[part 2 of 2]
AUTOSAR XML (schema 4-2-1)
package /GeneralMotorsPkg/GeneralMotorsArchitecturePkg/GeneralMotorsVehicleAbstractionPkg
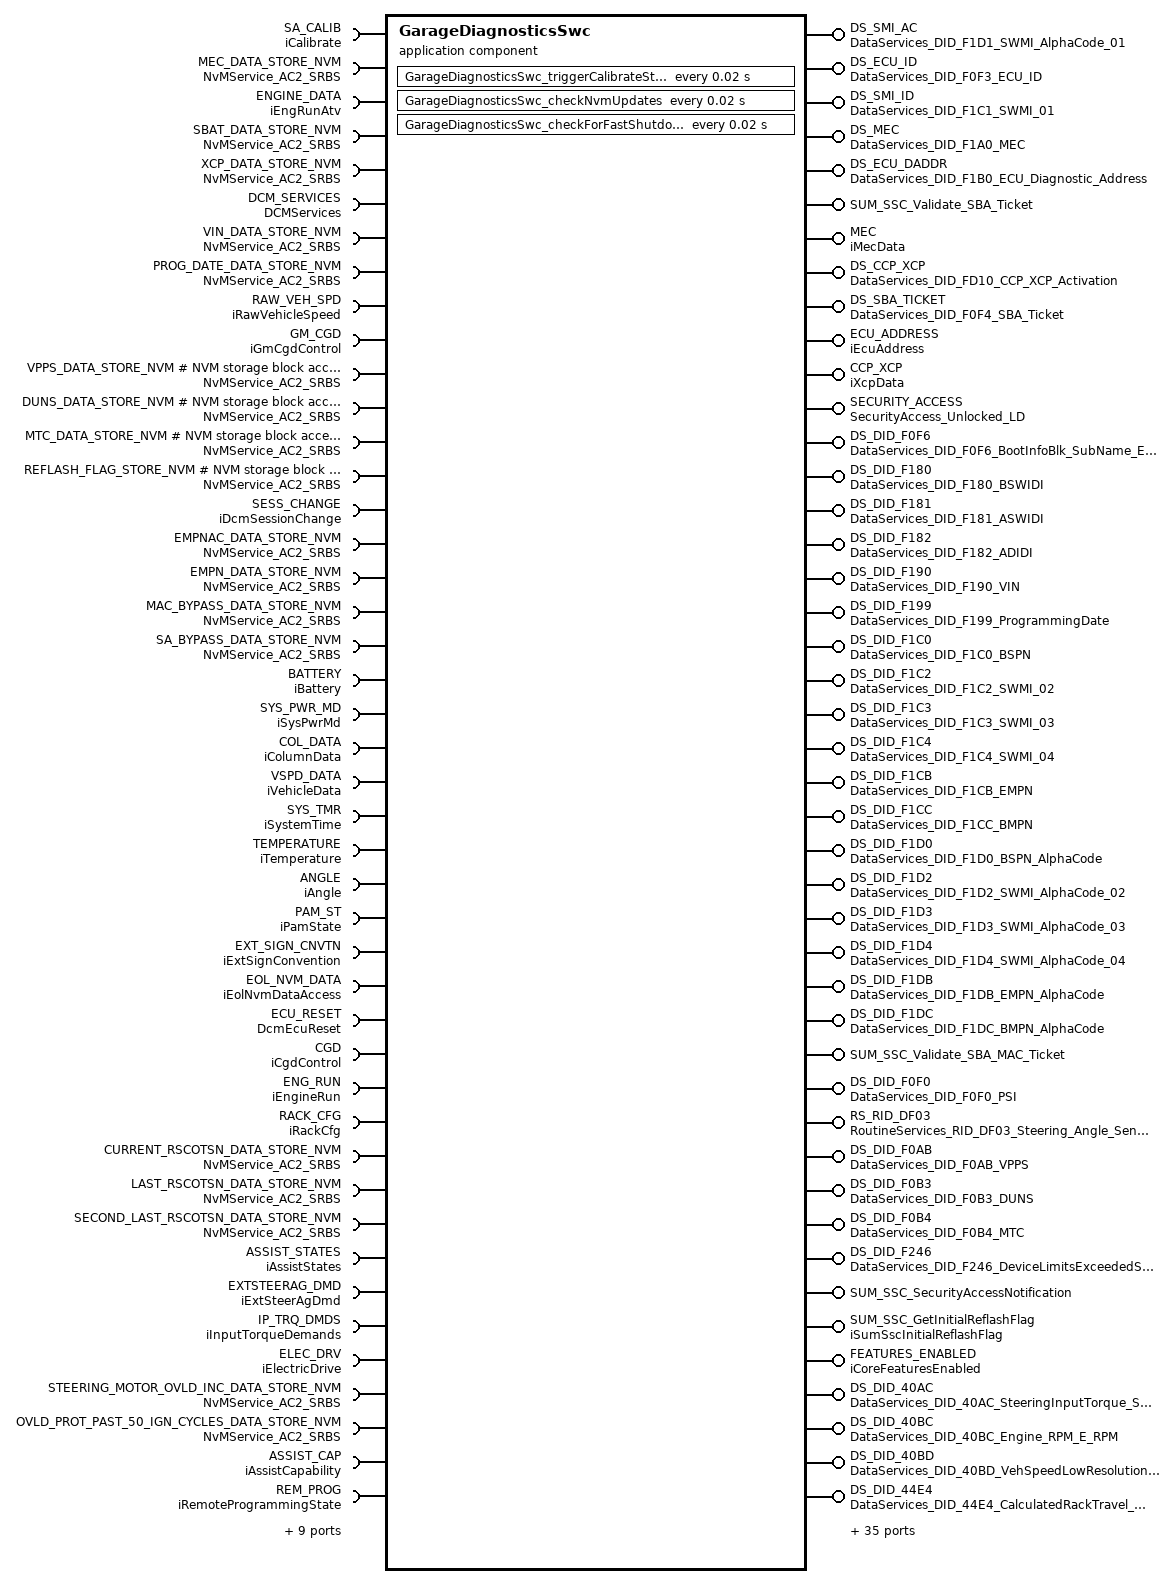
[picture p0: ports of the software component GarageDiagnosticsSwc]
  application sw component type GarageDiagnosticsSwc  # Garage Diagnostic allows the garage engineer to interface with the ECU software
    require port SA_CALIB: required-interface=iCalibrate  # Interface to call straight ahead calibration
    7 x provide port:
      DS_SMI_AC: server-com-spec{operation=ReadData, queue-length=1}, provided-interface=DataServices_DID_F1D1_SWMI_AlphaCode_01  # Full name: DataServices_Software_Module_Identifier_Alpha_Code_01_SWMI_AlphaCode_01
      DS_ECU_ID: server-com-spec{operation=ReadData, queue-length=1}, provided-interface=DataServices_DID_F0F3_ECU_ID  # Full name: DataServices_ECU_ID_EcuID
      DS_SMI_ID: server-com-spec{operation=ReadData, queue-length=1}, provided-interface=DataServices_DID_F1C1_SWMI_01  # Full name: DataServices_Software_Module_Identifier_01_SWMI_01
      DS_MEC: provided-com-specs=[{operation=ReadData, queue-length=1}, {operation=WriteData, queue-length=1}], provided-interface=DataServices_DID_F1A0_MEC  # Full name: DataServices_Manufacturers_Enable_Counter_MEC
      DS_ECU_DADDR: server-com-spec{operation=ReadData, queue-length=1}, provided-interface=DataServices_DID_F1B0_ECU_Diagnostic_Address  # Full name: DataServices_ECU_Diagnostic_Address_ECU_Address
      SUM_SSC_Validate_SBA_Ticket: server-com-spec{operation=Validate_SBA_Ticket, queue-length=1}, provided-interface=SUM_SSC_Validate_SBA_Ticket  # Interface used by SUM_SSC to validate all Security Bypass Authentication (SBA) Ticket
      MEC: nonqueued-sender-com-spec{data-element=MEC, init-value=constant-reference=iMecData_MEC_Init}, provided-interface=iMecData  # This port is used to allow the SUM_SSC access to the MEC value that is stored in the RTE. This is externally connected to SUM_DIAG_GetMEC
    require port MEC_DATA_STORE_NVM: required-interface=NvMService_AC2_SRBS  # Interface to access NVM store
    provide port DS_CCP_XCP: provided-com-specs=[{operation=ReadData, queue-length=1}, {operation=WriteData, queue-length=1}], provided-interface=DataServices_DID_FD10_CCP_XCP_Activation  # Full name: DataServices_CCP_XCP_Activation_CCP_XCP_Activation
    provide port DS_SBA_TICKET: provided-com-specs=[{operation=ReadData, queue-length=1}, {operation=WriteData, queue-length=1}], provided-interface=DataServices_DID_F0F4_SBA_Ticket  # Full name: DataServices_Signature_Bypass_Authorization_Ticket_SBATkt
    provide port ECU_ADDRESS: nonqueued-sender-com-spec{data-element=ECUAddress, init-value=constant-reference=iEcuAddress_ECUAddress_Init}, provided-interface=iEcuAddress  # This port is used to allow the SUM_SSC component to access the ECU Address. This is externally connected to SUM_SSC_GetECUAddress
    require port ENGINE_DATA: required-interface=iEngRunAtv  # Access to the engine data sent via CAN
      required-com-specs:
        data-element=EngineSpeed, init-value=constant-reference=iEngRunAtv_EngineSpeed_Init
        data-element=PowertrainCrankActive, init-value=constant-reference=iEngRunAtv_PowertrainCrankActive_Init
        data-element=Engine12VStarterMotorCmdOn, init-value=constant-reference=iEngRunAtv_Engine12VStarterMotorCmdOn_Init
    require port SBAT_DATA_STORE_NVM: required-interface=NvMService_AC2_SRBS  # Interface to access NVM store
    require port XCP_DATA_STORE_NVM: required-interface=NvMService_AC2_SRBS  # Interface to access NVM store
    provide port CCP_XCP: nonqueued-sender-com-spec{data-element=XcpStatus, init-value=constant-reference=iXcpData_XcpStatus_Init}, provided-interface=iXcpData  # Output the XCP status
    provide port SECURITY_ACCESS: provided-com-specs=[{operation=GetSeed, queue-length=1}, {operation=CompareKey, queue-length=1}], provided-interface=SecurityAccess_Unlocked_LD  # Security Access interfaces used by SUM_SSC
    require port DCM_SERVICES: required-interface=DCMServices  # Requests from the DCM component for CGD to do something
    18 x provide port:
      DS_DID_F0F6: server-com-spec{operation=ReadData, queue-length=1}, provided-interface=DataServices_DID_F0F6_BootInfoBlk_SubName_EcuName  # Boot Info Block Subject name and ECU name Subject name is an ECU family name. It is a 16 byte hexadecimal value that identifies the group of ECUs for which the Signer Info is applicable. It is used during the programming process to determine if the Signer Info is compatible with the target. Example: Powertrain, Infotainment, Telematics etc. ECU name is an 8 byte ASCII representation of the ECU name.
      DS_DID_F180: server-com-spec{operation=ReadData, queue-length=1}, provided-interface=DataServices_DID_F180_BSWIDI  # Boot Software Identification Data Identifier The BSWIDI is used to reference the vehicle-manufacturer-specific ECU boot software identification record. This DID is supported in all ECUs. The first data byte of the record data shall be the number of modules that are programmed in the ECU. If an ECU supports more than one BSWIDI at one time then this DID shall report the Fna, Part Number and DLS/PLS for each additional module. The numberOfModules shall reflect the total number of modules supported. If any modules are missing and the ECU can still report this DID the number of modules shall represent the number of modules that are currently programmed in the ECU. If no modules are programmed and the ECU can still report this DID the number of modules shall be zero. Note:The total number of bytes will vary depending on the number of modules programmed in the ECU.
      DS_DID_F181: server-com-spec{operation=ReadData, queue-length=1}, provided-interface=DataServices_DID_F181_ASWIDI  # Application Software Identification Data Identifier The ASWIDI is used to reference the vehicle-manufacturer-specific ECU application software identification record. This DID is supported in all ECUs as defined below. The first data byte of the data record shall be the total number of application software modules that are supported by the ECU. The application software module identification shall contain the Module Id, GM Part Number and GM Part Number Alpha Code as shown below. If an ECU supports more than one application software module then this DID shall report the Module Id , Part Number and Alpha Code for each additional application software module. If an application software module(s) is missing then the value of the application software module identification for the missing application software module(s) shall be zeroes. Note:The total number of bytes will vary depending on the number of modules programmed in the ECU.
      DS_DID_F182: server-com-spec{operation=ReadData, queue-length=1}, provided-interface=DataServices_DID_F182_ADIDI  # Application Data Identification Data Identifier The ADIDI is used to reference the vehicle-manufacturer-specific ECU calibration identification record. This DID is supported in all ECUs as defined below. The first data byte of the data record shall be the total number of calibration modules that are supported by the ECU. The calibration module identification shall contain the Module Id, GM Part Number and GM Part Number Alpha Code as shown below. If an ECU supports more than one calibration module then this DID shall report the Module Id, Part Number and Alpha Code for each additional calibration module. If a calibration module(s) is missing then the value of the calibration module identification for the missing calibration module(s) shall be zeroes. Note:The total number of bytes will vary depending on the number of modules programmed in the ECU.
      DS_DID_F190: provided-com-specs=[{operation=ReadData, queue-length=1}, {operation=WriteData, queue-length=1}], provided-interface=DataServices_DID_F190_VIN  # Vehicle Identification Number This DID contains the Vehicle Identification Number. The data content shall be specified by the vehicle manufacturer. If the VIN has not yet been programmed into the ECU permanent memory, those locations shall be either "$00" or "$FF". All 17 digits must be programmed in order for the ECU to use this DID.
      DS_DID_F199: provided-com-specs=[{operation=ReadData, queue-length=1}, {operation=WriteData, queue-length=1}], provided-interface=DataServices_DID_F199_ProgrammingDate  # Programming Date This DID contains the ProgrammingDate of the last programming event (SPS) at the dealer site. This BCD value is programmed into the ECU's memory during the last programming session (SPS).
      DS_DID_F1C0: server-com-spec{operation=ReadData, queue-length=1}, provided-interface=DataServices_DID_F1C0_BSPN  # BootSoftwarePartNumber (BSPN) This DID contains Boot Software Part Number information which is a 4-byte, unsigned numeric representation of the 8-digit GM part number assigned to the boot software of the ECU. If a Boot Software Alpha Code is used, then the Alpha Code associated with this part number shall be stored in DID $F1D0.
      DS_DID_F1C2: server-com-spec{operation=ReadData, queue-length=1}, provided-interface=DataServices_DID_F1C2_SWMI_02  # F1C2: SoftwareModule_02_Identifier This DID contains the Software Module Identifier (SWMI) 01 information used to uniquely identify a given software or calibration module. Each SWMI has a corresponding DID associated with it. ECUs are only required to support the DIDs which correspond to SWMIs valid for that ECU. The SWMI shall be included for each software module that can be separately programmed into the ECU permanent memory via the SPS. Individual software modules can contain operational software or calibration data. The SWMI information shall be stored using a four byte USN representation of the eight digit GM part number assigned to the software or calibration module. Each SWMI has a corresponding dataIdentifier associated with it. ECUs are only required to support the DIDs which correspond to SWMIs valid for that ECU.
      DS_DID_F1C3: server-com-spec{operation=ReadData, queue-length=1}, provided-interface=DataServices_DID_F1C3_SWMI_03  # F1C3: SoftwareModule_03_Identifier This DID contains the Software Module Identifier (SWMI) 01 information used to uniquely identify a given software or calibration module. Each SWMI has a corresponding DID associated with it. ECUs are only required to support the DIDs which correspond to SWMIs valid for that ECU. The SWMI shall be included for each software module that can be separately programmed into the ECU permanent memory via the SPS. Individual software modules can contain operational software or calibration data. The SWMI information shall be stored using a four byte USN representation of the eight digit GM part number assigned to the software or calibration module. Each SWMI has a corresponding dataIdentifier associated with it. ECUs are only required to support the DIDs which correspond to SWMIs valid for that ECU.
      DS_DID_F1C4: server-com-spec{operation=ReadData, queue-length=1}, provided-interface=DataServices_DID_F1C4_SWMI_04  # F1C4: SoftwareModule_04_Identifier This DID contains the Software Module Identifier (SWMI) 01 information used to uniquely identify a given software or calibration module. Each SWMI has a corresponding DID associated with it. ECUs are only required to support the DIDs which correspond to SWMIs valid for that ECU. The SWMI shall be included for each software module that can be separately programmed into the ECU permanent memory via the SPS. Individual software modules can contain operational software or calibration data. The SWMI information shall be stored using a four byte USN representation of the eight digit GM part number assigned to the software or calibration module. Each SWMI has a corresponding dataIdentifier associated with it. ECUs are only required to support the DIDs which correspond to SWMIs valid for that ECU.
      DS_DID_F1CB: server-com-spec{operation=ReadData, queue-length=1}, provided-interface=DataServices_DID_F1CB_EMPN  # End Model Part Number This DID is used to identify the part number that represents the combination of hardware/software/calibrations present in the ECU as it is received in the vehicle assembly plant. This part number is also used in service to uniquely identify the combination of hardware/software/calibrations programmed into the ECU at the time the part is ordered. Converting the four byte USN value to decimal provides the 8-digit part number assigned by the division. If an Alpha Code is used, then the Alpha Code associated with this part number shall be stored in dataIdentifier 0xF1DB.
      DS_DID_F1CC: server-com-spec{operation=ReadData, queue-length=1}, provided-interface=DataServices_DID_F1CC_BMPN  # Base Model Part Number This DID contains Base Model Part Number information which is used during SPS programming to identify a unique combination of ECU hardware and all non-reprogrammable software (e.g., Boot software). The BMPN must be stored in the ECU in a non-erasable memory area (e.g., boot sector of flash, or EEPROM). It shall not be possible to change the BMPN as part of a programming session or through diagnostic services when a programming session is not active. The BMPN of a service replacement ECU shall be identical to that of a Production ECU if both ECUs have the same hardware and non-reprogrammable software. If an Alpha Code is used, then the Alpha Code associated with this part number shall be stored in dataIdentifier $F1DC.
      DS_DID_F1D0: server-com-spec{operation=ReadData, queue-length=1}, provided-interface=DataServices_DID_F1D0_BSPN_AlphaCode  # Boot Software Part Number Alpha Code This DID contains a 2 character ASCII representation of the Alpha Code associated with the Boot Software Part Number (stored in DID 0xF1C0). The Alpha Code consists of a Design Level Suffix (DLS) and a Process Level Suffix (PLS). Byte 1 (DLS) This byte is contains an ASCII value that represents the major software release. This value shall initially be set to A and incremented as appropriate. Byte 2 (PLS) This byte is contains an ASCII value that represents the minor software revision. This value shall initially be set to A and incremented as appropriate.
      DS_DID_F1D2: server-com-spec{operation=ReadData, queue-length=1}, provided-interface=DataServices_DID_F1D2_SWMI_AlphaCode_02  # F1D2: SoftwareModule_02_AlphaCode This DID contains a 2 character ASCII representation of the Alpha Code for the corresponding Software Module Identifier 01-10, DID 0xF1C1 - 0xF1CA. The Alpha Code consists of a Design Level Suffix (DLS) and a Process Level Suffix (PLS). The SWMIs occupy the dataIdentifier range $F1C1 thru $F1CA. Reference the SWMI DID description for the numerical relationship between the DIDs used for the SWMI and the corresponding SWMIAC.
      DS_DID_F1D3: server-com-spec{operation=ReadData, queue-length=1}, provided-interface=DataServices_DID_F1D3_SWMI_AlphaCode_03  # F1D3: SoftwareModule_03_AlphaCode This DID contains a 2 character ASCII representation of the Alpha Code for the corresponding Software Module Identifier 01-10, DID 0xF1C1 - 0xF1CA. The Alpha Code consists of a Design Level Suffix (DLS) and a Process Level Suffix (PLS). The SWMIs occupy the dataIdentifier range $F1C1 thru $F1CA. Reference the SWMI DID description for the numerical relationship between the DIDs used for the SWMI and the corresponding SWMIAC.
      DS_DID_F1D4: server-com-spec{operation=ReadData, queue-length=1}, provided-interface=DataServices_DID_F1D4_SWMI_AlphaCode_04  # F1D4: SoftwareModule_04_AlphaCode This DID contains a 2 character ASCII representation of the Alpha Code for the corresponding Software Module Identifier 01-10, DID 0xF1C1 - 0xF1CA. The Alpha Code consists of a Design Level Suffix (DLS) and a Process Level Suffix (PLS). The SWMIs occupy the dataIdentifier range $F1C1 thru $F1CA. Reference the SWMI DID description for the numerical relationship between the DIDs used for the SWMI and the corresponding SWMIAC.
      DS_DID_F1DB: server-com-spec{operation=ReadData, queue-length=1}, provided-interface=DataServices_DID_F1DB_EMPN_AlphaCode  # End Model Part Number Alpha Code This DID contains the 2 character ASCII representation of the Alpha Code associated with the End Model Part Number (stored in DID 0XF1CB). The Alpha Code consists of a Design Level Suffix (DLS) and a Process Level Suffix (PLS). Byte 1 (DLS): This byte is contains an ASCII value that represents the hardware release. This value shall initially be set to A and incremented for a hardware revision. Byte 2 (PLS): This byte is contains an ASCII value that represents the software release. This value shall initially be set to A and incremented for a software revision.
      DS_DID_F1DC: server-com-spec{operation=ReadData, queue-length=1}, provided-interface=DataServices_DID_F1DC_BMPN_AlphaCode  # Base Model Part Number Alpha Code This DID contains the 2 character ASCII representation of the Alpha Code associated with the Base Model Part Number (stored in DID 0Xf1CC). The Alpha Code consists of a Design Level Suffix (DLS) and a Process Level Suffix (PLS). Byte 1 (DLS): This byte is contains an ASCII value that represents the hardware release. This value shall initially be set to A and incremented for a hardware revision. Byte 2 (PLS): This byte is contains an ASCII value that represents the software release. This value shall initially be set to A and incremented for a software revision.
    require port VIN_DATA_STORE_NVM: required-interface=NvMService_AC2_SRBS  # Interface to access NVM store
    require port PROG_DATE_DATA_STORE_NVM: required-interface=NvMService_AC2_SRBS  # Interface to access NVM store
    provide port SUM_SSC_Validate_SBA_MAC_Ticket: server-com-spec{operation=Validate_SBA_MAC_Ticket, queue-length=1}, provided-interface=SUM_SSC_Validate_SBA_MAC_Ticket  # Interface used by SUM_SSC to validate an individual MAC message Security Bypass Authentication (SBA) Ticket
    provide port DS_DID_F0F0: server-com-spec{operation=ReadData, queue-length=1}, provided-interface=DataServices_DID_F0F0_PSI  # ProgrammedStateIndicator (PSI) The Programmed State Indicator (PSI) data identifier provides a reliable mechanism for a Tester to determine if a logical partition is programmed with a valid content (i.e. Application software or calibration data). Each logical partition has a dedicated PSI that can be read using this DID. This means that there exist a PSI for application software partition and a PSI per calibration partition. This DID contains the ProgrammedStateIndicator. The Programmed State Indicator is a reserved cell (the last two bytes) in a flash partition that indicates the validity of the content for that partition. Each partition has a dedicated PSI that can be read using this DID. The first byte of the PSI DID denotes the partition number for the PSI that is being requested. Partition Number further defines a 4bit MSB and 4 Bit LSB. The 4 bit MSB defines the Processor ID (0: main processor, 1: 2nd processor, 2 : 3rd processor, etc..) and the 4 bit LSB defines the partition number (1: Application, 2: 1st cal partition, 3: 2nd cal partition, etc ..). For example Partition Numbers (in hex) have the following meaning. 0x01 : Main processor Application SW Partition 0x02 : Main processor 1st Cal Partition 0x03 : Main processor 2nd Cal Partition .. 0x11 : 2nd processor Application SW Partition 0x12 : 2nd processor 1st Cal Partition 0x13 : 2rd processor 2nd Cal Partition The second byte of the PSI DID denotes the programmed state of the partition. $00 = Valid programming present $01 = programming has been revoked $02 = programming is invalid $03 - $FF = Reserved Subsequent group of two bytes denote next calibration partition and the programmed state of the partition respectively. This pattern sequentially repeats for next partition and programmed state until 255th partition and its programmed state.
    require port RAW_VEH_SPD: nonqueued-receiver-com-spec{data-element=iRawVehicleSpeed/VehicleSpeed, init-value=constant-reference=iRawVehicleSpeed_VehicleSpeed_Init}, required-interface=iRawVehicleSpeed  # Access to the raw vehicle speed
    require port GM_CGD: required-interface=iGmCgdControl  # Tells the rest of the software that reset or switch to factory assist has been requested
    5 x provide port:
      RS_RID_DF03: provided-com-specs=[{operation=Start, queue-length=1}, {operation=RequestResults, queue-length=1}], provided-interface=RoutineServices_RID_DF03_Steering_Angle_Sensor_Calibration  # RoutineServices_RID_DF03_Steering_Angle_Sensor_Calibration_Start
      DS_DID_F0AB: server-com-spec{operation=ReadData, queue-length=1}, provided-interface=DataServices_DID_F0AB_VPPS  # DID 0xF0AB VPPS : Read : Interface to Nvm with 14 bytes and default value shall be taken from CGD : 2 0 . 0 1 . 0 4 . 9 7 0 0 X : Should be possible to be updated via XCP
      DS_DID_F0B3: server-com-spec{operation=ReadData, queue-length=1}, provided-interface=DataServices_DID_F0B3_DUNS  # DID 0xF0B3 DUNS : Read : Interface to Nvm with 9 bytes and default value shall be taken from CGD : 914666552 : Should be possible to be updated via XCP
      DS_DID_F0B4: server-com-spec{operation=ReadData, queue-length=1}, provided-interface=DataServices_DID_F0B4_MTC  # DID 0xF0B4 MTC : Read : Interface to Nvm with 16 bytes and default value shall be taken from CGD : all bytes "X" : Should be possible to be updated via XCP
      DS_DID_F246: server-com-spec{operation=ReadData, queue-length=1}, provided-interface=DataServices_DID_F246_DeviceLimitsExceededStatus  # DID 0xF246 Device Limits Exceeded : Should be accessed through 2 global variables shared with part Straight Ahead : 1) Routine Identifier(2 bytes) 2) Device Limits Exceeded Code (2 bytes):
    4 x require port, all with required-interface=NvMService_AC2_SRBS:
      VPPS_DATA_STORE_NVM  # NVM storage block access port for Compressed Vehicle Partitioning and Product Structure (VPPS)
      DUNS_DATA_STORE_NVM  # NVM storage block access port for Data Universal Numbering System Identification (DUNS)
      MTC_DATA_STORE_NVM  # NVM storage block access port for ManufacturingTraceabilityCharacters (MTC)
      REFLASH_FLAG_STORE_NVM  # NVM storage block access port for InitialReflashFlag
    provide port SUM_SSC_SecurityAccessNotification: server-com-spec{operation=ClearInitialReflashFlag, queue-length=1}, provided-interface=SUM_SSC_SecurityAccessNotification  # Interface between CGD and SUM_SSC to allow the SSC to clear the InitialReflashFlag
    provide port SUM_SSC_GetInitialReflashFlag: nonqueued-sender-com-spec{data-element=InitialReflashFlag, init-value=constant-reference=iSumSscInitialReflashFlag_InitialReflashFlag_Init}, provided-interface=iSumSscInitialReflashFlag  # Allows the SUM_SSC to get the InitialReflashFlag
    5 x require port:
      SESS_CHANGE: required-interface=iDcmSessionChange  # Session Change, informs CGD that the diagnostic session has changed.
      EMPNAC_DATA_STORE_NVM: required-interface=NvMService_AC2_SRBS  # NVM storage block access port for End Model Part Number Alpha Code (EMPNAC)
      EMPN_DATA_STORE_NVM: required-interface=NvMService_AC2_SRBS  # NVM storage block access port for End Model Part Number (EMPN)
      MAC_BYPASS_DATA_STORE_NVM: required-interface=NvMService_AC2_SRBS  # NVM storage block access port for Message Authentication Code (MAC) Bypass
      SA_BYPASS_DATA_STORE_NVM: required-interface=NvMService_AC2_SRBS  # NVM storage block access port for Security Access (SA) Bypass
    29 x provide port:
      FEATURES_ENABLED: provided-interface=iCoreFeaturesEnabled  # Tells the component if the feature has been enabled or not.
        provided-com-specs:
          data-element=DisturbanceRejectionEnabled, init-value=constant-reference=iCoreFeaturesEnabled_DisturbanceRejectionEnabled_Init
          data-element=DriverSteeringRecommendationEnabled, init-value=constant-reference=iCoreFeaturesEnabled_DriverSteeringRecommendationEnabled_Init
          data-element=FrictionCompensationEnabled, init-value=constant-reference=iCoreFeaturesEnabled_FrictionCompensationEnabled_Init
          data-element=HapticVibrationGeneratorEnabled, init-value=constant-reference=iCoreFeaturesEnabled_HapticVibrationGeneratorEnabled_Init
          data-element=LaneKeepingAssistEnabled, init-value=constant-reference=iCoreFeaturesEnabled_LaneKeepingAssistEnabled_Init
          data-element=ParkAssistEnabled, init-value=constant-reference=iCoreFeaturesEnabled_ParkAssistEnabled_Init
          data-element=PullDriftCompensationEnabled, init-value=constant-reference=iCoreFeaturesEnabled_PullDriftCompensationEnabled_Init
          data-element=RackEndStopEnabled, init-value=constant-reference=iCoreFeaturesEnabled_RackEndStopEnabled_Init
          data-element=RapidControlPrototypingEnabled, init-value=constant-reference=iCoreFeaturesEnabled_RapidControlPrototypingEnabled_Init
          data-element=SteerFeelSelectionEnabled, init-value=constant-reference=iCoreFeaturesEnabled_SteerFeelSelectionEnabled_Init
          data-element=SteeringPositionControllerEnabled, init-value=constant-reference=iCoreFeaturesEnabled_SteeringPositionControllerEnabled_Init
          data-element=StartStopEnabled, init-value=constant-reference=iCoreFeaturesEnabled_StartStopEnabled_Init
          data-element=ActiveReturnEnabled, init-value=constant-reference=iCoreFeaturesEnabled_ActiveReturnEnabled_Init
      DS_DID_40AC: server-com-spec{operation=ReadData, queue-length=1}, provided-interface=DataServices_DID_40AC_SteeringInputTorque_SIT  # DID 0x40AC: Read : Documentation: EPS_Diagnostic_CTS.docx Chapter 5.1.11.4 Steering Input Torque: s16_Torque (-128 to 127.996 Nm) y = (1/256)x Nm
      DS_DID_40BC: server-com-spec{operation=ReadData, queue-length=1}, provided-interface=DataServices_DID_40BC_Engine_RPM_E_RPM  # DID 0x40BC : Read : Documentation: EPS_Diagnostic_CTS.docx Chapter 5.1.11.8 Engine Speed: u16_Angular Velocity (0 to 16383.75 RPM) y = (1/4)x RPM
      DS_DID_40BD: server-com-spec{operation=ReadData, queue-length=1}, provided-interface=DataServices_DID_40BD_VehSpeedLowResolution_VSLR_VehSpeedLowResolution_B0  # DID 0x40BD : Read : Documentation: EPS_Diagnostic_CTS.docx Chapter 5.1.11.9 Vehicle Speed Low Resolution: u8_Velocity (0 to 255 km/h) y = x km/h
      DS_DID_44E4: server-com-spec{operation=ReadData, queue-length=1}, provided-interface=DataServices_DID_44E4_CalculatedRackTravel_CRT  # DID 0x44E4: Read : Documentation: EPS_Diagnostic_CTS.docx Chapter 5.1.11.28 Calculated Rack Travel: This PID is used to show the actual steering rack travel calculated by the EPS system. s16_Distance (-127.99 to 127.99mm) y = (1/256)x
      DS_DID_437A: server-com-spec{operation=ReadData, queue-length=1}, provided-interface=DataServices_DID_437A_EPP_SteeringMotorCurrentFeedback_STMCF  # DID 0x437A: Read : Documentation: GEM Diagnosis Functional Description.pdf Chapter 4.3.2.6.6.15 SteeringMotorCurrentFeedback Current Direction Definition: CCW---Positive, CW---- Negative Steering Motor Current Feedback is used to display the feedback current of the steering system. Size: s9 Byte: 0 -> Bits 7~1 (Reserved) Byte: 0 -> Bits 0 (SteeringMotorCurrentFeedback) Byte: 1 -> Bits 7~0 (SteeringMotorCurrentFeedback) Type: SN Resolution: 1 Range: -200~200
      DS_DID_437D: server-com-spec{operation=ReadData, queue-length=1}, provided-interface=DataServices_DID_437D_SteeringMotorOutputTorque_STMOT  # DID 0x437D: Read : Documentation: GEM Diagnosis Functional Description.pdf Chapter 4.3.2.6.6.17 SteeringMotorOutputTorque: Steering Motor Output Torque is used to display the current motor output torque of the steering system. Size: s11 Byte: 0 -> Bits 7~3 (Reserved) Byte: 0 -> Bits 2~0 (Steering Motor Output Torque) Byte: 1 -> Bits 7~0 (Steering Motor Output Torque) Scaling: E=N*0.01 Type: SN Units: Nm Resolution: 0.01 Range: -10 ~ 10
      DS_DID_437E: server-com-spec{operation=ReadData, queue-length=1}, provided-interface=DataServices_DID_437E_CalculatedSystemTemp_CSP  # DID 0x437E: Read : Documentation: GEM Diagnosis Functional Description.pdf Chapter 4.3.2.6.6.18 SteeringCalculatedSystemTemperature: Steering Calculated System Temperature is used to display the calculated internal ECU temperature the steering system. Size: u12 Byte: 0 -> Bits 7~4 (Reserved) Byte: 0 -> Bits 3~0 (SteeringCalculatedSystemTemperature) Byte: 1 -> Bits 7~0 (SteeringCalculatedSystemTemperature) Scaling: E=N*0.1-40 Type: USN Units: C Resolution: 0.1 Offset: 40 Range: -10 ~ 10
      DS_DID_819D: server-com-spec{operation=ReadData, queue-length=1}, provided-interface=DataServices_DID_819D_VehSpeedMediumResolution_VSMR  # DID 0x819D: Read : Documentation: EPS_Diagnostic_CTS.docx Chapter 5.1.11.20 Vehicle Speed Medium Resolution: Speed used in EPS Control Algorithms. u16_Velocity (0 to 1023.98 km/h) y = (1/64)x km/h
      DS_DID_4074: server-com-spec{operation=ReadData, queue-length=1}, provided-interface=DataServices_DID_4074_SteeringWheelAngle_SWA  # DID 0x4074: Read : Documentation: EPS_Diagnostic_CTS.docx Chapter 5.1.11.3 Steering Wheel Angle: The value of the Steering Wheel Angle shall follow ISO 8855 (i.e., Steering Wheel Angle is positive when rotated counterclockwise). s16_Angle (-2048 to 2047.94 deg) y = (1/16)x deg
      DS_DID_4370: server-com-spec{operation=ReadData, queue-length=1}, provided-interface=DataServices_DID_4370_SteeringSystemStatus_SSS  # DID 0x4370: Read : Documentation: GEM Diagnosis Functional Description.pdf Chapter 4.3.2.6.6.6 Steering System Status: Size: u2 Byte: 0 -> Bits 7~3 (Reserved) Byte: 0 -> Bits 2~0 (Steering System Status) S00:No Assist $01:No Assist during S/s $02:Full Assist $03:Limp Home $04: Limp Aside $05: Fade Type: ENUM
      DS_DID_4372: server-com-spec{operation=ReadData, queue-length=1}, provided-interface=DataServices_DID_4372_SteeringAdvancedParkingAssistState_APA  # DID 0x4372: Read : Documentation: GEM Diagnosis Functional Description.pdf Chapter 4.3.2.6.6.7 Steering Advanced Park Assist State: Steering Advanced Parking Assist State is used to display the current operating state of the advanced parking assist feature in steering system. Size: u2 Byte: 0 -> Bits 1~0 (Steering Advanced Park Assist States) $00: Temporarily Inhibited $01 : Available for Control $02 : Active $03 : Permanently Failed Type: ENUM
      DS_DID_4374: server-com-spec{operation=ReadData, queue-length=1}, provided-interface=DataServices_DID_4374_SteeringEndStopPositionLearnedStatus_SESPLS  # DID 0x4374: Read : Documentation: GEM Diagnosis Functional Description.pdf Chapter 4.3.2.6.6.9 Steering End Stop Position Learned Status: Steering End Stops Position Learned Status is used to display the learn status of the steering end stops position. Size: u1 Byte: 0 -> Bit 0 (SteeringEndStopsPstnLearndStatus) 1 = TRUE 0 =FALSE Type: Bool
      DS_DID_4376: server-com-spec{operation=ReadData, queue-length=1}, provided-interface=DataServices_DID_4376_TimeSinceIgnitionOn_TSIO  # DID 0x4376: Read : Documentation: GEM Diagnosis Functional Description.pdf Chapter 4.3.2.6.6.11 Time since Ignition On: Steering Time Since Ignition On is used to display the time elapsed since ignition is turned on. Size: u17 Byte: 0 -> Bits 7~1 (Reserved) Byte: 0 -> Bit 0 (Time since Ignition On) Byte: 1 -> Bits 7~0 (Time since Ignition On) Byte: 2 -> Bits 7~0 (Time since Ignition On) Scaling: E=N*1 Type: USN Resolution: UnitDef_LDWCSteering WheelAngleSignalDelay Range: 0~86400
      DS_DID_4377: server-com-spec{operation=ReadData, queue-length=1}, provided-interface=DataServices_DID_4377_VehicleParameters_VP  # DID 0x4377: Read : Documentation: GEM Diagnosis Functional Description.pdf Chapter 4.3.2.6.6.12 VehicleParameters: Steering Vehicle Speed is used to display the internal determined vehicle speed currently used in the steering system. Steering Engine Speed is used to display the internal determined engine speed currently used in the steering system. Steering Engine Running Status is used to indicate the engine running status determined internal to the steering system. Byte: 0 -> Bits 7~1 (Reserved) Byte: 0 -> Bit 0 (SteeringVehicleSpeed) Byte: 1 -> Bits 7~0 (SteeringVehicleSpeed) Size: u9 Scaling: E=N Type: USN Resolution: 1 Range: 0 ~ 400 Byte: 2 -> Bit 7 (Reserved) Byte: 2 -> Bits 6~0 (Steering Engine Speed) Byte: 3 -> Bits 7~1 (Steering Engine Speed) Size: u14 Scaling: E=N Type: USN Resolution: 1 Range: 0 ~ 15000 Byte: 3 -> Bit 0 (SteeringEngineRunningStatus) Scaling: 1 = TRUE 0 =FALSE Type: Bool
      DS_DID_4378: server-com-spec{operation=ReadData, queue-length=1}, provided-interface=DataServices_DID_4378_SteeringSupplierInternalDTC_FailureType_SSIIDTCFT  # DID 0x4378: Read : Documentation: GEM Diagnosis Functional Description.pdf Chapter 4.3.2.6.6.13 SteeringSupplierInternalDTC, SteeringSupplierInternalFailureType: Steering Supplier Internal DTC is used to display the corresponding supplier internal diagnostics code when a GM DTC is set. Steering Supplier Internal Failure Type is used to display the corresponding supplier internal diagnostics code type when a GM DTC is set. SteeringSupplierInternalDTC Size: u16 Byte: 0 & 1 Scaling: E=N Type: USN Resolution: 1 Range: 0 ~ 65535 SteeringSupplierInternalFailureType Size: u16 Byte: 2 & 3 Scaling: E=N Type: USN Resolution: 1 Range: 0 ~ 65535
      DS_DID_4379: server-com-spec{operation=ReadData, queue-length=1}, provided-interface=DataServices_DID_4379_SteeringMotorCurrentCommanded_SMCC  # DID 0x4379: Read : Documentation: GEM Diagnosis Functional Description.pdf Chapter 4.3.2.6.6.14 Steering Motor Current Commanded: Current Direction Definition: CCW---Positive, CW---- Negative Steering Motor Current Commanded is used to display the commanded motor current of the steering system. Byte: 0 -> Bits 7~1 (Reserved) Size: s9 Byte: 0 -> Bit 0 (SteeringMotorCurrentCommanded) Byte: 1 -> Bits 7~0 (SteeringMotorCurrentCommanded) Scaling: E=N Type: SN Resolution: 1 Range: -200~200
      DS_DID_4380: server-com-spec{operation=ReadData, queue-length=1}, provided-interface=DataServices_DID_4380_SteeringMotorOverloadProtectionIncidents_SMOPI  # DID 0x4380: Read : Documentation: GEM Diagnosis Functional Description.pdf Chapter 4.3.2.6.6.20 SteeringMotorOverloadProtectionIncidents: Steering Motor Overload Protection Incidents shall be incremented each time the EPS enters the reduced system performance mode (i.e. overload protection <80% of assist level). If no overload protection incident has occurred in the past 50 ignition cycles, the EPS Motor Overload Protection Incidents should be reset to 0. Size: u16 Byte: 0& 1 Scaling: E=N Type: USN Resolution: 1 Range: 0~65535
      DS_DID_4381: server-com-spec{operation=ReadData, queue-length=1}, provided-interface=DataServices_DID_4381_IgnCycleCounter_ICC  # DID 0x4381: Read : Documentation: GEM Diagnosis Functional Description.pdf Chapter 4.3.2.6.6.21 IgnitionCycleCounter: Ignition cycle is defined as Vehicle Power Mode transition from RUN to OFF back to RUN. Size: u16 Range 0~65535
      DS_DID_F0DF: provided-com-specs=[{operation=ReadData, queue-length=1}, {operation=WriteData, queue-length=1}], provided-interface=DataServices_DID_F0DF_ECU_OdometerValue_OdometerValue  # DID 0xF0DF: Read + Write : Documentation: GEM Diagnosis Functional Description.pdf Chapter 4.3.2.6.6.42 ECU Odometer Value: This DID contains the Odometer value as stored by the ECU. The odometer value shall be stored with a scaling of E = N / 64 km. Size: u32
      DS_DID_F1DE: server-com-spec{operation=ReadData, queue-length=1}, provided-interface=DataServices_DID_F1DE_ECU_CommunicationIdentificationData_CID  # DID 0xF1DE: Read : Documentation: PA0A2K - PATAC CLEA Family UDSonCAN Diagnostic Specification_GEM.pdf Page 131/247 ECU Communication Identification Data: Byte: 0 (Comm Ntwrk) Byte: 2&3&4 (AUTOSAR Version) Byte: 5&6&7 (ARXML Version) This DID is used to identify software revisions for system design artifacts released by GM. This DID contains a 1-byte Communication Network, a 3-byte AUTOSAR Version Number, and a 3-byte value that represents the ARXML version GM serial data database file implemented on the specified network. This information shall be repeated for each CAN Bus that the controller is connected to. The length of the DID will be determined by the number of connected Communication Networks, i.e., length is equal to 7*n, where n is the number of connected Communication Networks. This DID contains multiple fields as defined below: Communication Networks (Comm. Ntwrk) The first byte of this DID indicates which Networks the ECU is connected to, it is a one byte enumerated value. AUTOSAR Version This is the 3 bytes unsigned numeric value (starting at byte 2, and recurring at byte 9, byte 16, and following the sequence up to byte 142) which represnts the AUTOSAR version number. Basically, it specifies that which AUTOSAR version has been implemented by the ECU on the network specified by the preceding Communication Network. For the ECUs that do not support Autosar, it should be set to 0xFFFFFF. ARXML Version This is the 3 bytes unsigned numeric value starting at byte 5 (starting at byte 5, and recurring at byte 12, byte 19, and following the sequence up to byte 145) specifying the ARXML version. It indicates which PATAC ARXML Database version implemented by the ECU on the network specified by the preceding Communication Network. Note: This DID shall be supported by all ECUs. The totaol number of bytes will vary depending on the number of connected Communication Networks to the ECU.
      DS_DID_F085: server-com-spec{operation=ReadData, queue-length=1}, provided-interface=DataServices_DID_F085_SystemPowerMode_SystemPowerMode  # DID 0xF085: Read : Documentation: GEM Diagnosis Functional Description.pdf Chapter 4.3.2.6.6.35 Power Moding State Size: u8 0x00: OFF 0x01: ACCESSORY 0x02: RUN 0x03: STARTREQUEST 0x04: PROPULSION 0x05: TRANSPORT 0x06-0xFF: Reserved Type: ENUM
      DS_DID_437B: server-com-spec{operation=ReadData, queue-length=1}, provided-interface=DataServices_DID_437B_SteeringOverlayParameters_SOR  # DID 0x437B: Read : Documentation: GEM Diagnosis Functional Description.pdf Chapter 4.3.2.6.6.16 SteeringOverlayParameters SteerintAngleOverlayRequested Steering Angle Requested is used to display the amount of angle overlay currently requested to the steering system. Size: s16 Byte: 1 & 2 Scaling: E=0.1*N Type: SN Units: Degree Resolution: 0.1 Range: -740 ~ 740 SteerintTorqueOverlayRequested Steering Torque Overlay Requested is used to display the amount of torque overlay currently requested to the steering system. Size: s16 Byte: 3 & 4 Scaling: E=0.01*N Type: SN Units: Nm Resolution: 0.01 Range: -10 ~ 10 SteeringTorqueOverlayStatus Steering Torque Overlay Status is used to display the current torque overlay status of the steering system. - Inactive: Torque Interface disabled - Active: Torque Interface activated, EPS is providing the requested overlay torque - Temporarily Limited: EPS has limited the provided torque by the system safety limits or system capability - Permanently Failed: EPS has limited the provided torque because of a failure in the system. Size: 2 bits Byte: 0 Bits: 3~2 Scaling: $00: Inactive $01: Active $02 : Temporarily Limited $03 : Permanently Failed SteeringAngleOverlayStatus Steering Angle Overlay Status is used to display the current angle control status of the steering system. - Inactive: Angle Interface disabled - Active: Angle Interface activated, EPS is providing the requested angle command - Temporarily Limited: EPS has limited the angle control by the system safety limits or system capability - Permanently Failed: EPS has limited the angle control because of a failure in the system. Size: 2 bits Byte: 0 Bits: 1~0 Scaling: $00: Inactive $01: Active $02 : Temporarily Limited $03 : Permanently Failed
      DS_DID_4382: server-com-spec{operation=ReadData, queue-length=1}, provided-interface=DataServices_DID_4382_SAS_InternalStatusSteeringWheelAngleData_SAS  # DID 0x4382: Read : Documentation: GEM Diagnosis Functional Description.pdf Chapter 4.3.2.6.6.22 SteeringWheelAngleData: Steering Wheel Angle Mask (Don't Use Data) - This signal shall be used to indicate if the sensor has completed its internal self checks and the Steering Angle data is ready for use. The signal state shall be "True" when the sensor is ready for use and its internal self check has been completed. The signal state shall be "False" while the internal self testing is occurring or when the Steering Angle data is not ready for use. The SAS shall only run one self check per ignition cycle. It is expected to see during initial power up that the sensor shall broadcast "False" while the self check is occurring. Steering Wheel Angle Calibration Status - This signal shall be used to indicate the calibration status of the sensor. Only the "Unknown" or "Calibrated" states are valid for use. The signal state shall be "Unknown" so long as the sensor has never been through the calibration process or has been commanded to uncalibrate by a GM service tool. Once a sensor has been through the calibration process it will then change state to "Calibrated". Calibration status will not be in any way tied to Power mode. Steering Wheel Angle Gradient signal is an output signal proportional to the angle rate of change over the message periodic rate. Prior to sending of valid data, the SAS shall set the Steering Wheel Angle Mask (Don't Use Data) signal = False, and the Steering Wheel Angle and Steering Wheel Angle Gradient shall be set to a default value of zero. Data shall be transmitted during all Vehicle Power Mode. The SAS shall support a latency requirement of 5 msec. Byte: 0 -> Bits 7~3 (Reserved) SteeringWheelAngleMask Size: u1 Byte: 0 -> Bit 2 (SteeringWheelAngleMask) Scaling: 1 = TRUE 0 =FALSE Type: Bool SteeringWheelAngleCalbrtnStatus Size: u2 Byte: 0 -> Bits 1~0 (SteeringWheelAngleCalbrtnStatus) Scaling: $00 : Unknown $01: Estimated $02 : Calibrated Type: ENUM SteeringWheelAngleGradient Size: s16 Byte: 1 & 2 Scaling: E=N*0.0625 Type: SN Units: Deg/s Resolution: 0.0625 Range: -2048 ~ 2047.9375
      DS_DID_F09A: provided-com-specs=[{operation=ReadData, queue-length=1}, {operation=WriteData, queue-length=1}], provided-interface=DataServices_DID_F09A_DiagDataIdentifier_DiagDataIdentifier  # DID 0xF09A: Read + Write : Documentation: PA0A2K - PATAC CLEA Family UDSonCAN Diagnostic Specification_GEM.pdf Page 108/247 This Data Identifier contains the DiagnosticDataIdentifier which identifies a supplier and system specific diagnostic data stream and shall be used by diagnostic testers to interpret a diagnostic data stream. The data format of the DDI is defined as two (2) bytes where the most significant byte of the DDI identifies the system by a system code and the least significant byte identifies the system data stream version number. System Code (DDI high byte) shall be used to distinguish between the following cases: ? Different ECU systems, where the ECU uses the same Diagnostic Address ? Different system suppliers of the same component. ? Non-compatible ECU hardware and/or non-compatible software. Diagnostic Data Stream Version Number (DDI low byte) shall be incremented when: ?The diagnostic implementation is changed and the changes affect Service/Aftersales and/or Manufacturing diagnostic test tools.(Default Value for this byte:0x01) For a node which is not completely programmed, the value of the least significant byte of the DDI shall always be $00.
      DS_DID_F09F: server-com-spec{operation=ReadData, queue-length=1}, provided-interface=DataServices_DID_F09F_PreviousStoredRepairShopCodeOrTesterSerialNumbers_PSRSCOT  # DID 0xF09F: Read : Documentation: PA0A2K - PATAC CLEA Family UDSonCAN Diagnostic Specification_GEM.pdf Page 111/247 This Data Identifier contains the PreviousStoredRepairShopCodeOrTesterSerialNumbers. This data provides a mechanism for a tool user to identify up to the last two dealer codes or tester serial numbers programmed into Data Identifier $F198. All bytes in this Data Identifier shall be initialized by the ECU supplier to $20 (ASCII = space). Last Stored Repair Shop Codes or Tester Serial Number (Bytes #1 thru #10) When a tool writes a dealer code or tester serial number into Data Identifier $F198, the data previously stored in Data Identifier $F198 is copied (without additional tool intervention) into the module memory housing byte positions #1 through #10 of this Data Identifier. Second from Last Stored Repair Shop Codes or Tester Serial Number (Bytes #11 thru #20) When a tool writes a dealer code or tester serial number into Data Identifier $F198, the data previously in byte positions #1 through #10 of this Data Identifier are moved to positions #11 through #20. The data previously stored in Data Identifier $F198 are then copied into this Data Identifier in byte positions #1 through #10.
      DS_DID_F088: server-com-spec{operation=ReadData, queue-length=1}, provided-interface=DataServices_DID_F088_BatteryVoltage_State_BVS  # DID 0xF088: Read : Documentation: PA0A2K - PATAC CLEA Family UDSonCAN Diagnostic Specification_GEM.pdf Page 107/247 The Battery Voltage at the ECU connector in volts, BatteryVoltage E = (N * 0.1) + 3 The relationship between the enumerated states and the battery voltage A2D are defined in a project specific document. There are potentially multiple undervoltage levels defined in a project specific document. BatteryVoltageState 0x00: Normal 0x01: OverVoltage 0x02: UnderVoltage1 0x03: UnderVoltage2 0x04: UnderVoltage3 0x05: Undervoltage4 0x06 to 0xFF: Reserved
      DS_DID_F129: provided-com-specs=[{operation=ReadData, queue-length=1}, {operation=WriteData, queue-length=1}], provided-interface=DataServices_DID_F129_TotalVehicleOperationTime_TVOT  # DID 0xF129: Read + Write : Documentation: PA0A2K - PATAC CLEA Family UDSonCAN Diagnostic Specification_GEM.pdf Page 119/247 Total Vehicle Operation Time: Total Vehicle Operation Time is a running time counter that is incremented whenever any partial network on the vehicle is active. Vehicle Operation Time - Total is the accumulated value over the operational life of the vehicle. Timestamp - is one of the extended data record that is required to be stored by all ECUs while a DTC is logged. Total Vehicle Operation Time: E = N*100 Note: This DID shall be supported by all ECUs.
      DS_DID_F198: provided-com-specs=[{operation=ReadData, queue-length=1}, {operation=WriteData, queue-length=1}], provided-interface=DataServices_DID_F198_RepairShopCodeOrTesterSerialNumber_RSCOTSN  # DID 0xF198: Read + Write : Documentation: PA0A2K - PATAC CLEA Family UDSonCAN Diagnostic Specification_GEM.pdf Page 124/247 This DID contains the RepairShopCodeOrTesterSerialNumber which identifies the dealer's code or the tester's serial number. This ASCII string is programmed into the ECU's memory during the last programming session (SPS) at the dealer site.
    9 x require port:
      BATTERY: required-interface=iBattery  # Allows the status of the battery to be retrieved
      SYS_PWR_MD: nonqueued-receiver-com-spec{data-element=SysPwrMd, init-value=constant-reference=iSysPwrMd_SysPwrMd_Init}, required-interface=iSysPwrMd
      COL_DATA: required-interface=iColumnData
        required-com-specs:
          data-element=ColumnTorque, init-value=constant-reference=iColumnData_ColumnTorque_Init
          data-element=SteeringPositionLower, init-value=constant-reference=iColumnData_SteeringPositionLower_Init
          data-element=ColumnVelocity, init-value=constant-reference=iColumnData_ColumnVelocity_Init
          data-element=SteeringPositionUpper, init-value=constant-reference=iColumnData_SteeringPositionUpper_Init
          data-element=ColumnPositionLower, init-value=constant-reference=iColumnData_ColumnPositionLower_Init
          data-element=SteeringPositionCorrection, init-value=constant-reference=iColumnData_SteeringPositionCorrection_Init
      VSPD_DATA: required-interface=iVehicleData  # Receipt of the filtered vehicle speed
        required-com-specs:
          data-element=iVehicleData/VehicleSpeed, init-value=constant-reference=iVehicleData_VehicleSpeed_Init
          data-element=EstimatedSteeringPosition, init-value=constant-reference=iVehicleData_EstimatedSteeringPosition_Init
          data-element=YawRate, init-value=constant-reference=iVehicleData_YawRate_Init
      SYS_TMR: required-interface=iSystemTime  # Provides System Time from the EppAbstraction
      TEMPERATURE: required-interface=iTemperature  # Provides Internal measured temperatures from the EppAbstraction
      ANGLE: nonqueued-receiver-com-spec{data-element=Angle, init-value=constant-reference=iAngle_Angle_Init}, required-interface=iAngle
      PAM_ST: nonqueued-receiver-com-spec{data-element=PamState, init-value=constant-reference=iPamState_PamState_Init}, required-interface=iPamState  # Port to input Park Assist Manager state
      EXT_SIGN_CNVTN: parameter-require-com-spec{init-value=constant-reference=iExtSignConvention_SIGN_CONVENTION_Init, parameter=SIGN_CONVENTION}, required-interface=iExtSignConvention  # Access to sign convention parameter used to ensure correct sign polarity of column values exported to the vehicle.
    5 x provide port:
      SRSN_DiagSessionChangeRationalityCheck: provided-com-specs=[{operation=Indication, queue-length=1}, {operation=Confirmation, queue-length=1}], provided-interface=ServiceRequestNotification
      SRSN_ReadDataByIdRationalityCheck: provided-com-specs=[{operation=Indication, queue-length=1}, {operation=Confirmation, queue-length=1}], provided-interface=ServiceRequestNotification
      SRSN_RoutineControlRationalityCheck: provided-com-specs=[{operation=Indication, queue-length=1}, {operation=Confirmation, queue-length=1}], provided-interface=ServiceRequestNotification
      SRSN_WriteDataByIdRationalityCheck: provided-com-specs=[{operation=Indication, queue-length=1}, {operation=Confirmation, queue-length=1}], provided-interface=ServiceRequestNotification
      CGD_EntropyInterface: server-com-spec{operation=GenerateRandomNumber, queue-length=1}, provided-interface=EntropyInterface
    require port EOL_NVM_DATA: required-interface=iEolNvmDataAccess  # Allows the application to gain access to the End Of Line NVM data store from the EppAbstraction.
    provide port CGD_SHUTDOWN_ACTION: server-com-spec{operation=performShutdownAction, queue-length=1}, provided-interface=iPerformShutdownActions  # Allows CGD to perform any actions it needs to do before the VehicleStateSwc requests the shutdown.
    4 x require port:
      ECU_RESET: required-interface=DcmEcuReset  # Interface to provide information from DCM about newest reset request.
      CGD: required-interface=iCgdControl  # Number of interface that allow CGD (and therefore DID commands) to control the behavior of the ECU (for example before a reset).
      ENG_RUN: nonqueued-receiver-com-spec{data-element=EngineRun, init-value=constant-reference=iEngineRun_EngineRun_Init}, required-interface=iEngineRun
      RACK_CFG: required-interface=iRackCfg  # Port used to control rack config behaviours.
    provide port SUM_SSC_PropulsionSystemActive_If: nonqueued-sender-com-spec{data-element=PropulsionSystemActive, init-value=constant-reference=iSumSscPropulsionActiveIf_PropulsionSystemActive_Init}, provided-interface=iSumSscPropulsionActiveIf  # Allow the SUM SSC access to the vehicle speed data.
    provide port SUM_SSC_VehicleSpeed_If: nonqueued-sender-com-spec{data-element=iSumSscVehicleSpeedIf/VehicleSpeed, init-value=constant-reference=iSumSscVehicleSpeedIf_VehicleSpeed_Init}, provided-interface=iSumSscVehicleSpeedIf  # Allow the SUM SSC access to the vehicle speed data.
    11 x require port:
      CURRENT_RSCOTSN_DATA_STORE_NVM: required-interface=NvMService_AC2_SRBS  # NVM port to move data to storage block for Current Stored Repair Shop Code Or Tester Serial Numbers (RSCOTSN)
      LAST_RSCOTSN_DATA_STORE_NVM: required-interface=NvMService_AC2_SRBS  # NVM port to move data to storage block for Last Stored Repair Shop Code Or Tester Serial Numbers (RSCOTSN)
      SECOND_LAST_RSCOTSN_DATA_STORE_NVM: required-interface=NvMService_AC2_SRBS  # NVM port to move data to storage block for Second Last Stored Repair Shop Code Or Tester Serial Numbers (RSCOTSN)
      ASSIST_STATES: nonqueued-receiver-com-spec{data-element=AssistState, init-value=constant-reference=iAssistStates_AssistState_Init}, required-interface=iAssistStates  # Port provides assist state.
      EXTSTEERAG_DMD: nonqueued-receiver-com-spec{data-element=ExtSteerAgDmd, init-value=constant-reference=iExtSteerAgDmd_ExtSteerAgDmd_Init}, required-interface=iExtSteerAgDmd  # Port to receive external steering angle demand
      IP_TRQ_DMDS: required-interface=iInputTorqueDemands  # Torque demands, additional to the column torque, to be applied to the input side of the assist function
        required-com-specs:
          data-element=OverlayTorqueDemand, init-value=constant-reference=iInputTorqueDemands_OverlayTorqueDemand_Init
          data-element=LimitingTorqueDemand, init-value=constant-reference=iInputTorqueDemands_LimitingTorqueDemand_Init
      ELEC_DRV: required-interface=iElectricDrive  # This port is used for getting MotroTorqueEstimate value by getMotorTorqueEstimate operation.
      STEERING_MOTOR_OVLD_INC_DATA_STORE_NVM: required-interface=NvMService_AC2_SRBS  # Port to get counter incremented each time when the EPS enters into reduced performance mode.
      OVLD_PROT_PAST_50_IGN_CYCLES_DATA_STORE_NVM: required-interface=NvMService_AC2_SRBS  # Port to get counter which is incremented if during active journey EPS didn't entered into reduced system performance mode.
      ASSIST_CAP: nonqueued-receiver-com-spec{data-element=Capability, init-value=constant-reference=iAssistCapability_Capability_Init}, required-interface=iAssistCapability  # Port provides assist capability value.
      REM_PROG: nonqueued-receiver-com-spec{data-element=RemoteProgrammingState, init-value=constant-reference=iRemoteProgrammingState_RemoteProgrammingState_Init}, required-interface=iRemoteProgrammingState  # Port containing the remote programming state.
    provide port RS_RID_FF01: server-com-spec{operation=Start, queue-length=1}, provided-interface=RoutineServices_RID_FF01_CheckProgrammingDependencies  # RoutineServices_RID_FF01_CheckProgrammingDependencies.
    require port REM_PROG_STATE_NVM: required-interface=NvMService_AC2_SRBS  # NVM storage block access port for RemProgState.
    provide port REM_PROG_STATE_NVM_CBK: server-com-spec{operation=JobFinished, queue-length=1}, provided-interface=iNvmJobFinished
    provide port PROG_REQ: nonqueued-sender-com-spec{data-element=ProgState, init-value=constant-reference=iProgStateRequest_ProgState_Init}, provided-interface=iProgStateRequest  # Used to send Programming State requests.
    8 x require port:
      SUM_SSC_StrWhAngGrd: nonqueued-receiver-com-spec{data-element=SUM_SSC_StrWhAngGrd, init-value=constant-reference=iSumSscStrWhAngGrd_SUM_SSC_StrWhAngGrd_Init}, required-interface=iSumSscStrWhAngGrd  # Allow the CGD access to the Steering Wheel Angle Gradient.
      SUM_SSC_StrWhlAngSenCalStat: nonqueued-receiver-com-spec{data-element=SUM_SSC_StrWhlAngSenCalStat, init-value=constant-reference=iSumSscStrWhlAngSenCalStat_SUM_SSC_StrWhlAngSenCalStat_Init}, required-interface=iSumSscStrWhlAngSenCalStat  # Allow the CGD access to the Steering Wheel Angle Calibration Status.
      SUM_SSC_StrWhAngMsk: nonqueued-receiver-com-spec{data-element=SUM_SSC_StrWhAngMsk, init-value=constant-reference=iSumSscStrWhAngMsk_SUM_SSC_StrWhAngMsk_Init}, required-interface=iSumSscStrWhAngMsk  # Allow the CGD access to the Steering Wheel Angle Mask.
      SUM_SSC_StrWhAng: nonqueued-receiver-com-spec{data-element=SUM_SSC_StrWhAng, init-value=constant-reference=iSumSscStrWhAng_SUM_SSC_StrWhAng_Init}, required-interface=iSumSscStrWhAng  # This interface is intended to provide Angle sensor information after calculations.
      VIN_NOT_PROGRAMMED_MON: required-interface=DiagnosticMonitor
      VIN_NOT_PROGRAMMED_INFO: required-interface=DiagnosticInfo
      EOL_CALIBRATION_NOT_FLASHED_MON: required-interface=DiagnosticMonitor
      EOL_CALIBRATION_NOT_FLASHED_INFO: required-interface=DiagnosticInfo
    behavior GarageDiagnosticsSwc_IB: data-type-mapping=MappingSet, handle-termination-and-restart=NO-SUPPORT
      ar-typed-per-instance-memorys:
        17 x data, all with category=STRUCTURE, sw-calibration-access=READ-ONLY:
          MecDataStoreNvm: type=tMecDataStoreNvm, init-value=constant-reference=GarageDiagnosticsSwc_MecDataStoreNvm_Init
          SbaTicketDataStoreNvm: type=tSbaTicketDataStoreNvm, init-value=constant-reference=GarageDiagnosticsSwc_SbaTicketDataStoreNvm_Init
          ProgramDateDataStoreNvm: type=tProgramDateDataStoreNvm, init-value=constant-reference=GarageDiagnosticsSwc_ProgramDateDataStoreNvm_Init
          VppsDataStoreNvm: type=tVppsDataStoreNvm, init-value=constant-reference=GarageDiagnosticsSwc_VppsDataStoreNvm_Init
          DunsDataStoreNvm: type=tDunsDataStoreNvm, init-value=constant-reference=GarageDiagnosticsSwc_DunsDataStoreNvm_Init
          MtcDataStoreNvm: type=tMtcDataStoreNvm, init-value=constant-reference=GarageDiagnosticsSwc_MtcDataStoreNvm_Init
          InitialReflashFlagStoreNvm: type=tInitialReflashFlagStoreNvm, init-value=constant-reference=GarageDiagnosticsSwc_InitialReflashFlagStoreNvm_Init
          EmpnDataStoreNvm: type=tEmpnDataStoreNvm, init-value=constant-reference=GarageDiagnosticsSwc_EmpnDataStoreNvm_Init
          EmpnacDataStoreNvm: type=tEmpnacDataStoreNvm, init-value=constant-reference=GarageDiagnosticsSwc_EmpnacDataStoreNvm_Init
          MacBypassDataStoreNvm: type=tMacBypassDataStoreNvm, init-value=constant-reference=GarageDiagnosticsSwc_MacBypassDataStoreNvm_Init
          SaBypassDataStoreNvm: type=tSaBypassDataStoreNvm, init-value=constant-reference=GarageDiagnosticsSwc_SaBypassDataStoreNvm_Init
          CurrentRSCOTSNDataStoreNvm: type=tCurrentRSCOTSNDataStoreNvm, init-value=constant-reference=GarageDiagnosticsSwc_CurrentRSCOTSNDataStoreNvm_Init
          SecondLastRSCOTSNDataStoreNvm: type=tSecondLastRSCOTSNDataStoreNvm, init-value=constant-reference=GarageDiagnosticsSwc_SecondLastRSCOTSNDataStoreNvm_Init
          LastRSCOTSNDataStoreNvm: type=tLastRSCOTSNDataStoreNvm, init-value=constant-reference=GarageDiagnosticsSwc_LastRSCOTSNDataStoreNvm_Init
          StrgMotorOvldProtIncDataStoreNvm: type=tStrgMotorOvldProtIncDataStoreNvm, init-value=constant-reference=GarageDiagnosticsSwc_StrgMotorOvldProtIncDataStoreNvm_Init
          OvldProtPast50IgnCyclesDataStoreNvm: type=tOvldProtPast50IgnCyclesDataStoreNvm, init-value=constant-reference=GarageDiagnosticsSwc_OvldProtPast50IgnCyclesDataStoreNvm_Init
          RemProgStateNvm: type=tRemProgStateNvm, init-value=constant-reference=GarageDiagnosticsSwc_RemProgStateNvm_Init
      timing event Event_triggerCalibrateStraightAhead: start-on-event=GarageDiagnosticsSwc_triggerCalibrateStraightAhead, period=0.02
      9 x operation invoked event:
        Event_DS_SMI_AC_ReadData: start-on-event=GarageDiagnosticsSwc_DS_SMI_AC_ReadData, operation=DS_SMI_AC.ReadData
        Event_DS_ECU_ID_ReadData: start-on-event=GarageDiagnosticsSwc_DS_ECU_ID_ReadData, operation=DS_ECU_ID.ReadData
        Event_DS_SMI_ID_ReadData: start-on-event=GarageDiagnosticsSwc_DS_SMI_ID_ReadData, operation=DS_SMI_ID.ReadData
        Event_DS_ECU_DADDR_ReadData: start-on-event=GarageDiagnosticsSwc_DS_ECU_DADDR_ReadData, operation=DS_ECU_DADDR.ReadData
        Event_DS_MEC_WriteData: start-on-event=GarageDiagnosticsSwc_DS_MEC_WriteData, operation=DS_MEC.WriteData
        Event_DS_MEC_ReadData: start-on-event=GarageDiagnosticsSwc_DS_MEC_ReadData, operation=DS_MEC.ReadData
        Event_DS_CCP_XCP_ReadData: start-on-event=GarageDiagnosticsSwc_DS_CCP_XCP_ReadData, operation=DS_CCP_XCP.ReadData
        Event_DS_SBA_TICKET_ReadData: start-on-event=GarageDiagnosticsSwc_DS_SBA_TICKET_ReadData, operation=DS_SBA_TICKET.ReadData
        Event_DS_SBA_TICKET_WriteData: start-on-event=GarageDiagnosticsSwc_DS_SBA_TICKET_WriteData, operation=DS_SBA_TICKET.WriteData
      init event Event_initialiser_Init: start-on-event=GarageDiagnosticsSwc_initialiser
      33 x operation invoked event:
        Event_DS_CCP_XCP_WriteData: start-on-event=GarageDiagnosticsSwc_DS_CCP_XCP_WriteData, operation=DS_CCP_XCP.WriteData
        Event_SECURITY_ACCESS_GetSeed: start-on-event=GarageDiagnosticsSwc_SECURITY_ACCESS_GetSeed, operation=SECURITY_ACCESS.GetSeed
        Event_SECURITY_ACCESS_CompareKey: start-on-event=GarageDiagnosticsSwc_SECURITY_ACCESS_CompareKey, operation=SECURITY_ACCESS.CompareKey
        Event_SUM_SSC_Validate_SBA_Ticket_Validate_SBA_Ticket: start-on-event=GarageDiagnosticsSwc_SUM_SSC_Validate_SBA_Ticket_Validate_SBA_Ticket, operation=SUM_SSC_Validate_SBA_Ticket.Validate_SBA_Ticket
        Event_DS_DID_F0F0_ReadData: start-on-event=GarageDiagnosticsSwc_DS_DID_F0F0_ReadData, operation=DS_DID_F0F0.ReadData
        Event_DS_DID_F{180..182}_ReadData: start-on-event=GarageDiagnosticsSwc_DS_DID_F{180..182}_ReadData, operation=DS_DID_F{180..182}.ReadData
        Event_DS_DID_F190_ReadData: start-on-event=GarageDiagnosticsSwc_DS_DID_F190_ReadData, operation=DS_DID_F190.ReadData
        Event_DS_DID_F199_ReadData: start-on-event=GarageDiagnosticsSwc_DS_DID_F199_ReadData, operation=DS_DID_F199.ReadData
        Event_DS_DID_F1C0_ReadData: start-on-event=GarageDiagnosticsSwc_DS_DID_F1C0_ReadData, operation=DS_DID_F1C0.ReadData
        Event_DS_DID_F1C2_ReadData: start-on-event=GarageDiagnosticsSwc_DS_DID_F1C2_ReadData, operation=DS_DID_F1C2.ReadData
        Event_DS_DID_F1CB_ReadData: start-on-event=GarageDiagnosticsSwc_DS_DID_F1CB_ReadData, operation=DS_DID_F1CB.ReadData
        Event_DS_DID_F1CC_ReadData: start-on-event=GarageDiagnosticsSwc_DS_DID_F1CC_ReadData, operation=DS_DID_F1CC.ReadData
        Event_DS_DID_F1D0_ReadData: start-on-event=GarageDiagnosticsSwc_DS_DID_F1D0_ReadData, operation=DS_DID_F1D0.ReadData
        Event_DS_DID_F1D{2..4}_ReadData: start-on-event=GarageDiagnosticsSwc_DS_DID_F1D{2..4}_ReadData, operation=DS_DID_F1D{2..4}.ReadData
        Event_DS_DID_F1DB_ReadData: start-on-event=GarageDiagnosticsSwc_DS_DID_F1DB_ReadData, operation=DS_DID_F1DB.ReadData
        Event_DS_DID_F1DC_ReadData: start-on-event=GarageDiagnosticsSwc_DS_DID_F1DC_ReadData, operation=DS_DID_F1DC.ReadData
        Event_DS_DID_F1C3_ReadData: start-on-event=GarageDiagnosticsSwc_DS_DID_F1C3_ReadData, operation=DS_DID_F1C3.ReadData
        Event_DS_DID_F1C4_ReadData: start-on-event=GarageDiagnosticsSwc_DS_DID_F1C4_ReadData, operation=DS_DID_F1C4.ReadData
        Event_DS_DID_F190_WriteData: start-on-event=GarageDiagnosticsSwc_DS_DID_F190_WriteData, operation=DS_DID_F190.WriteData
        Event_DS_DID_F199_WriteData: start-on-event=GarageDiagnosticsSwc_DS_DID_F199_WriteData, operation=DS_DID_F199.WriteData
        Event_SUM_SSC_Validate_SBA_Ticket_Validate_SBA_MAC_Ticket: start-on-event=GarageDiagnosticsSwc_SUM_SSC_Validate_SBA_Ticket_Validate_SBA_MAC_Ticket, operation=SUM_SSC_Validate_SBA_MAC_Ticket.Validate_SBA_MAC_Ticket
        Event_DS_DID_F0F6_ReadData: start-on-event=GarageDiagnosticsSwc_DS_DID_F0F6_ReadData, operation=DS_DID_F0F6.ReadData
        Event_RS_RID_DF03_Start: start-on-event=GarageDiagnosticsSwc_RS_RID_DF03_Start, operation=RS_RID_DF03.Start
        Event_DS_DID_F0AB_ReadData: start-on-event=GarageDiagnosticsSwc_DS_DID_F0AB_ReadData, operation=DS_DID_F0AB.ReadData
        Event_DS_DID_F0B3_ReadData: start-on-event=GarageDiagnosticsSwc_DS_DID_F0B3_ReadData, operation=DS_DID_F0B3.ReadData
        Event_DS_DID_F0B4_ReadData: start-on-event=GarageDiagnosticsSwc_DS_DID_F0B4_ReadData, operation=DS_DID_F0B4.ReadData
        Event_DS_DID_F246_ReadData: start-on-event=GarageDiagnosticsSwc_DS_DID_F246_ReadData, operation=DS_DID_F246.ReadData
        Event_SUM_SSC_SecurityAccessNotification_ClearInitialReflashFlag: start-on-event=GarageDiagnosticsSwc_SUM_SSC_SecurityAccessNotification_ClearInitialReflashFlag, operation=SUM_SSC_SecurityAccessNotification.ClearInitialReflashFlag
        Event_RS_RID_DF03_RequestResults: start-on-event=GarageDiagnosticsSwc_RS_RID_DF03_RequestResults, operation=RS_RID_DF03.RequestResults
      timing event Event_checkNvmUpdates: start-on-event=GarageDiagnosticsSwc_checkNvmUpdates, period=0.02
      41 x operation invoked event:
        Event_DS_DID_4074_ReadData: start-on-event=GarageDiagnosticsSwc_DS_DID_4074_ReadData, operation=DS_DID_4074.ReadData
        Event_DS_DID_40AC_ReadData: start-on-event=GarageDiagnosticsSwc_DS_DID_40AC_ReadData, operation=DS_DID_40AC.ReadData
        Event_DS_DID_40BC_ReadData: start-on-event=GarageDiagnosticsSwc_DS_DID_40BC_ReadData, operation=DS_DID_40BC.ReadData
        Event_DS_DID_40BD_ReadData: start-on-event=GarageDiagnosticsSwc_DS_DID_40BD_ReadData, operation=DS_DID_40BD.ReadData
        Event_DS_DID_4370_ReadData: start-on-event=GarageDiagnosticsSwc_DS_DID_4370_ReadData, operation=DS_DID_4370.ReadData
        Event_DS_DID_4372_ReadData: start-on-event=GarageDiagnosticsSwc_DS_DID_4372_ReadData, operation=DS_DID_4372.ReadData
        Event_DS_DID_4374_ReadData: start-on-event=GarageDiagnosticsSwc_DS_DID_4374_ReadData, operation=DS_DID_4374.ReadData
        Event_DS_DID_{4376..4379}_ReadData: start-on-event=GarageDiagnosticsSwc_DS_DID_{4376..4379}_ReadData, operation=DS_DID_{4376..4379}.ReadData
        Event_DS_DID_437A_ReadData: start-on-event=GarageDiagnosticsSwc_DS_DID_437A_ReadData, operation=DS_DID_437A.ReadData
        Event_DS_DID_437B_ReadData: start-on-event=GarageDiagnosticsSwc_DS_DID_437B_ReadData, operation=DS_DID_437B.ReadData
        Event_DS_DID_437D_ReadData: start-on-event=GarageDiagnosticsSwc_DS_DID_437D_ReadData, operation=DS_DID_437D.ReadData
        Event_DS_DID_437E_ReadData: start-on-event=GarageDiagnosticsSwc_DS_DID_437E_ReadData, operation=DS_DID_437E.ReadData
        Event_DS_DID_{4380..4382}_ReadData: start-on-event=GarageDiagnosticsSwc_DS_DID_{4380..4382}_ReadData, operation=DS_DID_{4380..4382}.ReadData
        Event_DS_DID_44E4_ReadData: start-on-event=GarageDiagnosticsSwc_DS_DID_44E4_ReadData, operation=DS_DID_44E4.ReadData
        Event_DS_DID_819D_ReadData: start-on-event=GarageDiagnosticsSwc_DS_DID_819D_ReadData, operation=DS_DID_819D.ReadData
        Event_DS_DID_F085_ReadData: start-on-event=GarageDiagnosticsSwc_DS_DID_F085_ReadData, operation=DS_DID_F085.ReadData
        Event_DS_DID_F088_ReadData: start-on-event=GarageDiagnosticsSwc_DS_DID_F088_ReadData, operation=DS_DID_F088.ReadData
        Event_DS_DID_F09A_ReadData: start-on-event=GarageDiagnosticsSwc_DS_DID_F09A_ReadData, operation=DS_DID_F09A.ReadData
        Event_DS_DID_F09F_ReadData: start-on-event=GarageDiagnosticsSwc_DS_DID_F09F_ReadData, operation=DS_DID_F09F.ReadData
        Event_DS_DID_F0DF_ReadData: start-on-event=GarageDiagnosticsSwc_DS_DID_F0DF_ReadData, operation=DS_DID_F0DF.ReadData
        Event_DS_DID_F129_ReadData: start-on-event=GarageDiagnosticsSwc_DS_DID_F129_ReadData, operation=DS_DID_F129.ReadData
        Event_DS_DID_F198_ReadData: start-on-event=GarageDiagnosticsSwc_DS_DID_F198_ReadData, operation=DS_DID_F198.ReadData
        Event_DS_DID_F1DE_ReadData: start-on-event=GarageDiagnosticsSwc_DS_DID_F1DE_ReadData, operation=DS_DID_F1DE.ReadData
        Event_DS_DID_F0DF_WriteData: start-on-event=GarageDiagnosticsSwc_DS_DID_F0DF_WriteData, operation=DS_DID_F0DF.WriteData
        Event_DS_DID_F09A_WriteData: start-on-event=GarageDiagnosticsSwc_DS_DID_F09A_WriteData, operation=DS_DID_F09A.WriteData
        Event_DS_DID_F129_WriteData: start-on-event=GarageDiagnosticsSwc_DS_DID_F129_WriteData, operation=DS_DID_F129.WriteData
        Event_DS_DID_F198_WriteData: start-on-event=GarageDiagnosticsSwc_DS_DID_F198_WriteData, operation=DS_DID_F198.WriteData
        Event_SRSN_DiagSessionChangeRationalityCheck_Indication: start-on-event=GarageDiagnosticsSwc_SRSN_DiagSessionChangeRationalityCheck_Indication, operation=SRSN_DiagSessionChangeRationalityCheck.Indication
        Event_SRSN_ReadDataByIdRationalityCheck_Indication: start-on-event=GarageDiagnosticsSwc_SRSN_ReadDataByIdRationalityCheck_Indication, operation=SRSN_ReadDataByIdRationalityCheck.Indication
        Event_SRSN_RoutineControlRationalityCheck_Indication: start-on-event=GarageDiagnosticsSwc_SRSN_RoutineControlRationalityCheck_Indication, operation=SRSN_RoutineControlRationalityCheck.Indication
        Event_SRSN_WriteDataByIdRationalityCheck_Indication: start-on-event=GarageDiagnosticsSwc_SRSN_WriteDataByIdRationalityCheck_Indication, operation=SRSN_WriteDataByIdRationalityCheck.Indication
        Event_SRSN_DiagSessionChangeRationalityCheck_Confirmation: start-on-event=GarageDiagnosticsSwc_SRSN_DiagSessionChangeRationalityCheck_Confirmation, operation=SRSN_DiagSessionChangeRationalityCheck.Confirmation
        Event_SRSN_ReadDataByIdRationalityCheck_Confirmation: start-on-event=GarageDiagnosticsSwc_SRSN_ReadDataByIdRationalityCheck_Confirmation, operation=SRSN_ReadDataByIdRationalityCheck.Confirmation
        Event_SRSN_RoutineControlRationalityCheck_Confirmation: start-on-event=GarageDiagnosticsSwc_SRSN_RoutineControlRationalityCheck_Confirmation, operation=SRSN_RoutineControlRationalityCheck.Confirmation
        Event_SRSN_WriteDataByIdRationalityCheck_Confirmation: start-on-event=GarageDiagnosticsSwc_SRSN_WriteDataByIdRationalityCheck_Confirmation, operation=SRSN_WriteDataByIdRationalityCheck.Confirmation
        Event_GenerateRandomNumber: start-on-event=GarageDiagnosticsSwc_GenerateRandomNumber, operation=CGD_EntropyInterface.GenerateRandomNumber
      timing event Event_checkForFastShutdown: start-on-event=GarageDiagnosticsSwc_checkForFastShutdown, period=0.02
      operation invoked event Event_performShutdownAction: start-on-event=GarageDiagnosticsSwc_performShutdownAction, operation=CGD_SHUTDOWN_ACTION.performShutdownAction
      4 x timing event, all with period=0.02:
        Event_checkEcuReset: start-on-event=GarageDiagnosticsSwc_checkEcuReset
        Event_provideDataToSums: start-on-event=GarageDiagnosticsSwc_provideDataToSums
        Event_calculateTimeSinceIgnitionOn: start-on-event=GarageDiagnosticsSwc_calculateTimeSinceIgnitionOn
        Event_checkSteeringMotorOverloadProtectionIncidents: start-on-event=GarageDiagnosticsSwc_checkSteeringMotorOverloadProtectionIncidents
      operation invoked event Event_RS_RID_FF01_Start: start-on-event=GarageDiagnosticsSwc_RS_RID_FF01_Start, operation=RS_RID_FF01.Start
      operation invoked event Event_JobFinished_RemProgStateNvm: start-on-event=GarageDiagnosticsSwc_JobFinished_RemProgStateNvm, operation=REM_PROG_STATE_NVM_CBK.JobFinished
      explicit-inter-runnable-variables:
        7 x data, all with sw-calibration-access=READ-ONLY:
          RoutineIdentifier: type=UInt16, init-value=constant-reference=GarageDiagnosticsSwc_RoutineIdentifier_Init  # Global to CGD variables shared with parts Straight Ahead Routine Identifier(2 bytes)
          DeviceLimitsExceededCode: type=UInt16, init-value=constant-reference=GarageDiagnosticsSwc_DeviceLimitsExceededCode_Init  # Global to CGD variables shared with parts Straight Ahead Device Limits Exceeded Code (2 bytes)
          CalculatedTimeSinceIgnitionOn: type=UInt32, init-value=constant-reference=GarageDiagnosticsSwc_CalculatedTimeSinceIgnitionOn_Init  # IRV to provide information from runnable to DID about Time elapsed since ingition on.
          MotorOverloadProtectionOccurred: type=Boolean, init-value=constant-reference=GarageDiagnosticsSwc_MotorOverloadProtectionOccurred_Init  # IRV to provide information from runnable to inform if EPS has entered into reduced performance mode. Basing on this value counters Steering Motor Overload Protection Incidents and Overload protection past 50 ignition cycles are beeing incremented.
          SID_28_CommControlStatus: type=tCommControlStatusSID28, init-value=constant-reference=GarageDiagnosticsSwc_SID_28_CommControlStatus_Init  # Indicates if communications are enabled or disabled (by UDS Service 0x28).
          RemProgStateNvmJobStatus: type=tCgdNvmJobStatus, init-value=constant-reference=GarageDiagnosticsSwc_RemProgStateNvmJobStatus_Init  # NVM current job status.
          XcpEnabled: type=Boolean, init-value=constant-reference=GarageDiagnosticsSwc_XcpEnabled_Init  # This IRV is needed to store and share information about XCP interface status between initializer and check for fast shutdown runnable. IRV can be updated by EnableXCP DID and in initializer when the value is readed from NVM. FALSE - XCP DISABLED TRUE - XCP ENABLED
      per-instance-parameters:
        25 x parameter data prototype:
          APA_FEATURE_ENABLED_FLAG: category=VALUE, sw-addr-method=FeatureTune, sw-calibration-access=READ-WRITE, type=Boolean, init-value=constant-reference=FeatureTune_APA_FEATURE_ENABLED_FLAG_Init  # Declares if the APA feature should be enabled or not. TRUE = Enabled (default) FALSE = Disabled
          CGD_VEH_SPEED_RAT_CHECK_THR: category=VALUE, sw-addr-method=VehicleTune, sw-calibration-access=READ-WRITE, type=Kph_0_0_to_400_0, init-value=constant-reference=VehicleTune_CGD_VEH_SPEED_RAT_CHECK_THR_Init  # Vehicle Speed threshold for rationality check. Prevents from executing number of services.
          CGD_OVERVOLT_THR: category=VALUE, sw-addr-method=VehicleTune, sw-calibration-access=READ-WRITE, type=Volts_16_0_to_30_0, init-value=constant-reference=VehicleTune_CGD_OVERVOLT_THR_Init  # Voltage threshold to allow DID detect battery range. This threshold is configured and defined by customer.
          CGD_UNDERVOLT_1_THR: category=VALUE, sw-addr-method=VehicleTune, sw-calibration-access=READ-WRITE, type=Volts_9_0_to_10_0, init-value=constant-reference=VehicleTune_CGD_UNDERVOLT_1_THR_Init  # Voltage threshold to allow DID detect battery range. This threshold is configured and defined by customer.
          CGD_UNDERVOLT_2_THR: category=VALUE, sw-addr-method=VehicleTune, sw-calibration-access=READ-WRITE, type=Volts_6_5_to_9_0, init-value=constant-reference=VehicleTune_CGD_UNDERVOLT_2_THR_Init  # Voltage threshold to allow DID detect battery range. This threshold is configured and defined by customer.
          CGD_UNDERVOLT_3_THR: category=VALUE, sw-addr-method=VehicleTune, sw-calibration-access=READ-WRITE, type=Volts_5_9_to_6_5, init-value=constant-reference=VehicleTune_CGD_UNDERVOLT_3_THR_Init  # Voltage threshold to allow DID detect battery range. This threshold is configured and defined by customer.
          CGD_UNDERVOLT_4_THR: category=VALUE, sw-addr-method=VehicleTune, sw-calibration-access=READ-WRITE, type=Volts_0_1_to_5_9, init-value=constant-reference=VehicleTune_CGD_UNDERVOLT_4_THR_Init  # Voltage threshold to allow DID detect battery range. This threshold is configured and defined by customer.
          XCP_TIMEOUT: category=VALUE, sw-addr-method=VehicleTune, sw-calibration-access=READ-WRITE, type=Sec_0_1_to_5_0, init-value=constant-reference=VehicleTune_XCP_TIMEOUT_Init  # Time parameter to allow DID timeout detection of NVM writing XCP parameter.
          MecDataStoreNvm_DEFAULT_VALUE: category=RECORD, type=tMecDataStoreNvm, init-value=constant-reference=GarageDiagnosticsSwc_MecDataStoreNvm_Init
          SbaTicketDataStoreNvm_DEFAULT_VALUE: category=RECORD, type=tSbaTicketDataStoreNvm, init-value=constant-reference=GarageDiagnosticsSwc_SbaTicketDataStoreNvm_Init
          ProgramDateDataStoreNvm_DEFAULT_VALUE: category=RECORD, type=tProgramDateDataStoreNvm, init-value=constant-reference=GarageDiagnosticsSwc_ProgramDateDataStoreNvm_Init
          VppsDataStoreNvm_DEFAULT_VALUE: category=RECORD, type=tVppsDataStoreNvm, init-value=constant-reference=GarageDiagnosticsSwc_VppsDataStoreNvm_Init
          DunsDataStoreNvm_DEFAULT_VALUE: category=RECORD, type=tDunsDataStoreNvm, init-value=constant-reference=GarageDiagnosticsSwc_DunsDataStoreNvm_Init
          MtcDataStoreNvm_DEFAULT_VALUE: category=RECORD, type=tMtcDataStoreNvm, init-value=constant-reference=GarageDiagnosticsSwc_MtcDataStoreNvm_Init
          InitialReflashFlagStoreNvm_DEFAULT_VALUE: category=RECORD, type=tInitialReflashFlagStoreNvm, init-value=constant-reference=GarageDiagnosticsSwc_InitialReflashFlagStoreNvm_Init
          EmpnDataStoreNvm_DEFAULT_VALUE: category=RECORD, type=tEmpnDataStoreNvm, init-value=constant-reference=GarageDiagnosticsSwc_EmpnDataStoreNvm_Init
          EmpnacDataStoreNvm_DEFAULT_VALUE: category=RECORD, type=tEmpnacDataStoreNvm, init-value=constant-reference=GarageDiagnosticsSwc_EmpnacDataStoreNvm_Init
          MacBypassDataStoreNvm_DEFAULT_VALUE: category=RECORD, type=tMacBypassDataStoreNvm, init-value=constant-reference=GarageDiagnosticsSwc_MacBypassDataStoreNvm_Init
          SaBypassDataStoreNvm_DEFAULT_VALUE: category=RECORD, type=tSaBypassDataStoreNvm, init-value=constant-reference=GarageDiagnosticsSwc_SaBypassDataStoreNvm_Init
          CurrentRSCOTSNDataStoreNvm_DEFAULT_VALUE: category=RECORD, type=tCurrentRSCOTSNDataStoreNvm, init-value=constant-reference=GarageDiagnosticsSwc_CurrentRSCOTSNDataStoreNvm_Init
          SecondLastRSCOTSNDataStoreNvm_DEFAULT_VALUE: category=RECORD, type=tSecondLastRSCOTSNDataStoreNvm, init-value=constant-reference=GarageDiagnosticsSwc_SecondLastRSCOTSNDataStoreNvm_Init
          LastRSCOTSNDataStoreNvm_DEFAULT_VALUE: category=RECORD, type=tLastRSCOTSNDataStoreNvm, init-value=constant-reference=GarageDiagnosticsSwc_LastRSCOTSNDataStoreNvm_Init
          StrgMotorOvldProtIncDataStoreNvm_DEFAULT_VALUE: category=RECORD, type=tStrgMotorOvldProtIncDataStoreNvm, init-value=constant-reference=GarageDiagnosticsSwc_StrgMotorOvldProtIncDataStoreNvm_Init
          OvldProtPast50IgnCyclesDataStoreNvm_DEFAULT_VALUE: category=RECORD, type=tOvldProtPast50IgnCyclesDataStoreNvm, init-value=constant-reference=GarageDiagnosticsSwc_OvldProtPast50IgnCyclesDataStoreNvm_Init
          RemProgStateNvm_DEFAULT_VALUE: category=RECORD, type=tRemProgStateNvm, init-value=constant-reference=GarageDiagnosticsSwc_RemProgStateNvm_Init
      94 x runnable:
        GarageDiagnosticsSwc_triggerCalibrateStraightAhead: symbol=GarageDiagnostics_triggerCalibrateStraightAhead  # (20ms) Triggers straight ahead calibration (calibration or erase) based on XCP request after checking that the vehicle is not moving and provides feedback
          sync call Call_DCM_SERVICES_GetSecurityLevel: operation=DCM_SERVICES.GetSecurityLevel, timeout=0
          written-local-variables:
            access WV_DeviceLimitsExceededCode: accessed-variable=DeviceLimitsExceededCode
            access WV_RoutineIdentifier: accessed-variable=RoutineIdentifier
        GarageDiagnosticsSwc_DS_SMI_AC_ReadData: symbol=GarageDiagnostics_DS_SMI_AC_ReadData
        GarageDiagnosticsSwc_DS_ECU_ID_ReadData: symbol=GarageDiagnostics_DS_ECU_ID_ReadData
        GarageDiagnosticsSwc_DS_SMI_ID_ReadData: symbol=GarageDiagnostics_DS_SMI_ID_ReadData
        GarageDiagnosticsSwc_DS_ECU_DADDR_ReadData: symbol=GarageDiagnostics_DS_ECU_DADDR_ReadData
        GarageDiagnosticsSwc_DS_MEC_WriteData: symbol=GarageDiagnostics_DS_MEC_WriteData
          data-send-points:
            access W_MEC_MEC: accessed-variable=MEC.MEC
            access W_CCP_XCP_XcpStatus: accessed-variable=CCP_XCP.XcpStatus
          sync call Call_MEC_DATA_STORE_NVM_WriteBlock: operation=MEC_DATA_STORE_NVM.WriteBlock, timeout=0
          sync call Call_DCM_SERVICES_GetSecurityLevel: operation=DCM_SERVICES.GetSecurityLevel, timeout=0
        GarageDiagnosticsSwc_DS_MEC_ReadData: symbol=GarageDiagnostics_DS_MEC_ReadData
        GarageDiagnosticsSwc_DS_CCP_XCP_ReadData: symbol=GarageDiagnostics_DS_CCP_XCP_ReadData
          read-local-variables:
            access RV_XcpEnabled: accessed-variable=XcpEnabled
        GarageDiagnosticsSwc_DS_SBA_TICKET_ReadData: symbol=GarageDiagnostics_DS_SBA_TICKET_ReadData
        GarageDiagnosticsSwc_DS_SBA_TICKET_WriteData: symbol=GarageDiagnostics_DS_SBA_TICKET_WriteData
          sync call Call_SBAT_DATA_STORE_NVM_WriteBlock: operation=SBAT_DATA_STORE_NVM.WriteBlock, timeout=0
        GarageDiagnosticsSwc_initialiser: symbol=GarageDiagnostics_initialiser  # Initialiser runnable, run at initialisation, to clear and set default values for variables. This runnable checks the NVM recovery of the MEC value. If it is valid it keeps the value, if it is invalid the MEC value of 0x00 is written (which locks the unit). Note this is different to the initial value of MEC which 0xFE which is used when a new unit is programmed.
          data-read-access:
            access R_RAW_VEH_SPD_VehicleSpeed: accessed-variable=RAW_VEH_SPD.VehicleSpeed
          data-write-access:
            5 x access:
              W_ECU_ADDRESS_ECUAddress: accessed-variable=ECU_ADDRESS.ECUAddress
              W_MEC_MEC: accessed-variable=MEC.MEC
              W_CCP_XCP_XcpStatus: accessed-variable=CCP_XCP.XcpStatus
              W_FEATURES_ENABLED_ParkAssistEnabled: accessed-variable=FEATURES_ENABLED.ParkAssistEnabled
              W_PROG_REQ_ProgState: accessed-variable=PROG_REQ.ProgState
          parameter access APA_FEATURE_ENABLED_FLAG: accessed-parameter=APA_FEATURE_ENABLED_FLAG
          sync call Call_SESS_CHANGE_SessionChange: operation=SESS_CHANGE.SessionChange, timeout=0
          sync call Call_CGD_resetRequest: operation=CGD.resetRequest, timeout=0
          written-local-variables:
            access WV_XcpEnabled: accessed-variable=XcpEnabled
        GarageDiagnosticsSwc_DS_CCP_XCP_WriteData: symbol=GarageDiagnostics_DS_CCP_XCP_WriteData
          data-send-points:
            access W_CCP_XCP_XcpStatus: accessed-variable=CCP_XCP.XcpStatus
          parameter access XCP_TIMEOUT: accessed-parameter=XCP_TIMEOUT
          sync call Call_SYS_TMR_getSystemTime: operation=SYS_TMR.getSystemTime, timeout=0
          written-local-variables:
            access WV_XcpEnabled: accessed-variable=XcpEnabled
        GarageDiagnosticsSwc_SECURITY_ACCESS_GetSeed: can-be-invoked-concurrently=true, symbol=GarageDiagnostics_SECURITY_ACCESS_GetSeed
          sync call Call_DCM_SERVICES_GetSecurityLevel: operation=DCM_SERVICES.GetSecurityLevel, timeout=0
        GarageDiagnosticsSwc_SECURITY_ACCESS_CompareKey: can-be-invoked-concurrently=true, symbol=GarageDiagnostics_SECURITY_ACCESS_CompareKey
          sync call Call_DCM_SERVICES_SetSecurityLevel: operation=DCM_SERVICES.SetSecurityLevel, timeout=0
        GarageDiagnosticsSwc_SUM_SSC_Validate_SBA_Ticket_Validate_SBA_Ticket: symbol=GarageDiagnostics_SUM_SSC_Validate_SBA_Ticket_Validate_SBA_Ticket
        GarageDiagnosticsSwc_DS_DID_F0F0_ReadData: symbol=GarageDiagnostics_DS_DID_F0F0_ReadData
        GarageDiagnosticsSwc_DS_DID_F{180..182}_ReadData: symbol=GarageDiagnostics_DS_DID_F{180..182}_ReadData
        GarageDiagnosticsSwc_DS_DID_F190_ReadData: symbol=GarageDiagnostics_DS_DID_F190_ReadData
        GarageDiagnosticsSwc_DS_DID_F199_ReadData: symbol=GarageDiagnostics_DS_DID_F199_ReadData
        GarageDiagnosticsSwc_DS_DID_F1C0_ReadData: symbol=GarageDiagnostics_DS_DID_F1C0_ReadData
        GarageDiagnosticsSwc_DS_DID_F1C2_ReadData: symbol=GarageDiagnostics_DS_DID_F1C2_ReadData
        GarageDiagnosticsSwc_DS_DID_F1CB_ReadData: symbol=GarageDiagnostics_DS_DID_F1CB_ReadData
        GarageDiagnosticsSwc_DS_DID_F1CC_ReadData: symbol=GarageDiagnostics_DS_DID_F1CC_ReadData
        GarageDiagnosticsSwc_DS_DID_F1D0_ReadData: symbol=GarageDiagnostics_DS_DID_F1D0_ReadData
        GarageDiagnosticsSwc_DS_DID_F1D{2..4}_ReadData: symbol=GarageDiagnostics_DS_DID_F1D{2..4}_ReadData
        GarageDiagnosticsSwc_DS_DID_F1DB_ReadData: symbol=GarageDiagnostics_DS_DID_F1DB_ReadData
        GarageDiagnosticsSwc_DS_DID_F1DC_ReadData: symbol=GarageDiagnostics_DS_DID_F1DC_ReadData
        GarageDiagnosticsSwc_DS_DID_F1C3_ReadData: symbol=GarageDiagnostics_DS_DID_F1C3_ReadData
        GarageDiagnosticsSwc_DS_DID_F1C4_ReadData: symbol=GarageDiagnostics_DS_DID_F1C4_ReadData
        GarageDiagnosticsSwc_DS_DID_F190_WriteData: symbol=GarageDiagnostics_DS_DID_F190_WriteData
          sync call Call_VIN_DATA_STORE_NVM_WriteBlock: operation=VIN_DATA_STORE_NVM.WriteBlock, timeout=0
        GarageDiagnosticsSwc_DS_DID_F199_WriteData: symbol=GarageDiagnostics_DS_DID_F199_WriteData
          sync call Call_PROG_DATE_DATA_STORE_NVM_WriteBlock: operation=PROG_DATE_DATA_STORE_NVM.WriteBlock, timeout=0
        GarageDiagnosticsSwc_SUM_SSC_Validate_SBA_Ticket_Validate_SBA_MAC_Ticket: symbol=GarageDiagnostics_SUM_SSC_Validate_SBA_Ticket_Validate_SBA_MAC_Ticket
        GarageDiagnosticsSwc_DS_DID_F0F6_ReadData: symbol=GarageDiagnostics_DS_DID_F0F6_ReadData
        GarageDiagnosticsSwc_RS_RID_DF03_Start: symbol=GarageDiagnostics_RS_RID_DF03_Start
          sync call Call_SA_CALIB_calibrateStraightAhead: operation=SA_CALIB.calibrateStraightAhead, timeout=0
          sync call Call_SA_CALIB_getCalibrateStatus: operation=SA_CALIB.getCalibrateStatus, timeout=0
          written-local-variables:
            access WV_DeviceLimitsExceededCode: accessed-variable=DeviceLimitsExceededCode
            access WV_RoutineIdentifier: accessed-variable=RoutineIdentifier
        GarageDiagnosticsSwc_DS_DID_F0AB_ReadData: symbol=GarageDiagnostics_DS_DID_F0AB_ReadData
        GarageDiagnosticsSwc_DS_DID_F0B3_ReadData: symbol=GarageDiagnostics_DS_DID_F0B3_ReadData
        GarageDiagnosticsSwc_DS_DID_F0B4_ReadData: symbol=GarageDiagnostics_DS_DID_F0B4_ReadData
        GarageDiagnosticsSwc_DS_DID_F246_ReadData: symbol=GarageDiagnostics_DS_DID_F246_ReadData
          read-local-variables:
            access RV_DeviceLimitsExceededCode: accessed-variable=DeviceLimitsExceededCode
            access RV_RoutineIdentifier: accessed-variable=RoutineIdentifier
        GarageDiagnosticsSwc_SUM_SSC_SecurityAccessNotification_ClearInitialReflashFlag: symbol=GarageDiagnostics_SUM_SSC_SecurityAccessNotification_ClearInitialReflashFlag
          data-send-points:
            access W_SUM_SSC_GetInitialReflashFlag_InitialReflashFlag: accessed-variable=SUM_SSC_GetInitialReflashFlag.InitialReflashFlag
          sync call Call_REFLASH_FLAG_STORE_NVM_WriteBlock: operation=REFLASH_FLAG_STORE_NVM.WriteBlock, timeout=0
        GarageDiagnosticsSwc_RS_RID_DF03_RequestResults: symbol=GarageDiagnostics_RS_RID_DF03_RequestResults
        GarageDiagnosticsSwc_checkNvmUpdates: symbol=GarageDiagnostics_checkNvmUpdates  # Check that an NVM update has been updated via XCP (which can be read via the Pim); if so triggers a save of the requested data block.
          8 x sync call, all with timeout=0:
            Call_EOL_CALIBRATION_NOT_FLASHED_SetEventStatus: operation=EOL_CALIBRATION_NOT_FLASHED_MON.SetEventStatus
            Call_EOL_CALIBRATION_NOT_FLASHED_ResetEventStatus: operation=EOL_CALIBRATION_NOT_FLASHED_MON.ResetEventDebounceStatus
            Call_EOL_CALIBRATION_NOT_FLASHED_GetEventStatus: operation=EOL_CALIBRATION_NOT_FLASHED_INFO.GetEventStatus
            Call_EOL_CALIBRATION_NOT_FLASHED_GetEventFailed: operation=EOL_CALIBRATION_NOT_FLASHED_INFO.GetEventFailed
            Call_VIN_NOT_PROGRAMMED_SetEventStatus: operation=VIN_NOT_PROGRAMMED_MON.SetEventStatus
            Call_VIN_NOT_PROGRAMMED_ResetEventStatus: operation=VIN_NOT_PROGRAMMED_MON.ResetEventDebounceStatus
            Call_VIN_NOT_PROGRAMMED_GetEventStatus: operation=VIN_NOT_PROGRAMMED_INFO.GetEventStatus
            Call_VIN_NOT_PROGRAMMED_GetEventFailed: operation=VIN_NOT_PROGRAMMED_INFO.GetEventFailed
        GarageDiagnosticsSwc_DS_DID_4074_ReadData: symbol=GarageDiagnostics_DS_DID_4074_ReadData
          data-receive-point-by-arguments:
            access R_SUM_SSC_StrWhAng_SUM_SSC_StrWhAng: accessed-variable=SUM_SSC_StrWhAng.SUM_SSC_StrWhAng
            access R_ANGLE_Angle: accessed-variable=ANGLE.Angle
        GarageDiagnosticsSwc_DS_DID_40AC_ReadData: symbol=GarageDiagnostics_DS_DID_40AC_ReadData
          data-receive-point-by-arguments:
            access R_COL_DATA_ColumnTorque: accessed-variable=COL_DATA.ColumnTorque
        GarageDiagnosticsSwc_DS_DID_40BC_ReadData: symbol=GarageDiagnostics_DS_DID_40BC_ReadData
          data-receive-point-by-arguments:
            access R_ENGINE_DATA_EngineSpeed: accessed-variable=ENGINE_DATA.EngineSpeed
        GarageDiagnosticsSwc_DS_DID_40BD_ReadData: symbol=GarageDiagnostics_DS_DID_40BD_ReadData
          data-receive-point-by-arguments:
            access R_VSPD_DATA_VehicleSpeed: accessed-variable=VSPD_DATA.VehicleSpeed
        GarageDiagnosticsSwc_DS_DID_4370_ReadData: symbol=GarageDiagnostics_DS_DID_4370_ReadData
          data-receive-point-by-arguments:
            access R_ASSIST_STATES_AssistState: accessed-variable=ASSIST_STATES.AssistState
        GarageDiagnosticsSwc_DS_DID_4372_ReadData: symbol=GarageDiagnostics_DS_DID_4372_ReadData
          data-receive-point-by-arguments:
            access R_PAM_ST_PamState: accessed-variable=PAM_ST.PamState
        GarageDiagnosticsSwc_DS_DID_4374_ReadData: symbol=GarageDiagnostics_DS_DID_4374_ReadData
          sync call Call_RACK_CFG_isRackEndStopPositionsLearned: operation=RACK_CFG.isRackEndStopPositionsLearned, timeout=0
        GarageDiagnosticsSwc_DS_DID_4376_ReadData: symbol=GarageDiagnostics_DS_DID_4376_ReadData
          read-local-variables:
            access RV_CalculatedTimeSinceIgnitionOn: accessed-variable=CalculatedTimeSinceIgnitionOn
        GarageDiagnosticsSwc_DS_DID_4377_ReadData: symbol=GarageDiagnostics_DS_DID_4377_ReadData
          data-receive-point-by-arguments:
            access R_ENGINE_DATA_EngineSpeed: accessed-variable=ENGINE_DATA.EngineSpeed
            access R_VSPD_DATA_VehicleSpeed: accessed-variable=VSPD_DATA.VehicleSpeed
            access R_ENG_RUN_EngineRun: accessed-variable=ENG_RUN.EngineRun
        GarageDiagnosticsSwc_DS_DID_4378_ReadData: symbol=GarageDiagnostics_DS_DID_4378_ReadData
        GarageDiagnosticsSwc_DS_DID_4379_ReadData: symbol=GarageDiagnostics_DS_DID_4379_ReadData
        GarageDiagnosticsSwc_DS_DID_437A_ReadData: symbol=GarageDiagnostics_DS_DID_437A_ReadData
        GarageDiagnosticsSwc_DS_DID_437B_ReadData: symbol=GarageDiagnostics_DS_DID_437B_ReadData
          data-receive-point-by-arguments:
            access R_EXTSTEERAG_DMD_ExtSteerAgDmd: accessed-variable=EXTSTEERAG_DMD.ExtSteerAgDmd
            access R_IP_TRQ_DMDS_OverlayTorqueDemand: accessed-variable=IP_TRQ_DMDS.OverlayTorqueDemand
        GarageDiagnosticsSwc_DS_DID_437D_ReadData: symbol=GarageDiagnostics_DS_DID_437D_ReadData
          sync call Call_ELEC_DRV_getMotorTorqueEstimate: operation=ELEC_DRV.getMotorTorqueEstimate, timeout=0
        GarageDiagnosticsSwc_DS_DID_437E_ReadData: symbol=GarageDiagnostics_DS_DID_437E_ReadData
          sync call Call_TEMPERATURE_getDriveStageTemperature: operation=TEMPERATURE.getDriveStageTemperature, timeout=0
        GarageDiagnosticsSwc_DS_DID_4380_ReadData: symbol=GarageDiagnostics_DS_DID_4380_ReadData
        GarageDiagnosticsSwc_DS_DID_4381_ReadData: symbol=GarageDiagnostics_DS_DID_4381_ReadData
        GarageDiagnosticsSwc_DS_DID_4382_ReadData: symbol=GarageDiagnostics_DS_DID_4382_ReadData
          data-receive-point-by-arguments:
            access R_SUM_SSC_StrWhAngGrd_SUM_SSC_StrWhAngGrd: accessed-variable=SUM_SSC_StrWhAngGrd.SUM_SSC_StrWhAngGrd
            access R_SUM_SSC_StrWhlAngSenCalStat_SUM_SSC_StrWhlAngSenCalStat: accessed-variable=SUM_SSC_StrWhlAngSenCalStat.SUM_SSC_StrWhlAngSenCalStat
            access R_SUM_SSC_StrWhAngMsk_SUM_SSC_StrWhAngMsk: accessed-variable=SUM_SSC_StrWhAngMsk.SUM_SSC_StrWhAngMsk
        GarageDiagnosticsSwc_DS_DID_44E4_ReadData: symbol=GarageDiagnostics_DS_DID_44E4_ReadData
        GarageDiagnosticsSwc_DS_DID_819D_ReadData: symbol=GarageDiagnostics_DS_DID_819D_ReadData
          data-receive-point-by-arguments:
            access R_RAW_VEH_SPD_VehicleSpeed: accessed-variable=RAW_VEH_SPD.VehicleSpeed
        GarageDiagnosticsSwc_DS_DID_F085_ReadData: symbol=GarageDiagnostics_DS_DID_F085_ReadData
          data-receive-point-by-arguments:
            access R_SYS_PWR_MD_SysPwrMd: accessed-variable=SYS_PWR_MD.SysPwrMd
        GarageDiagnosticsSwc_DS_DID_F088_ReadData: symbol=GarageDiagnostics_DS_DID_F088_ReadData
          5 x parameter access:
            CGD_OVERVOLT_THR: accessed-parameter=CGD_OVERVOLT_THR
            CGD_UNDERVOLT_{1..4}_THR: accessed-parameter=CGD_UNDERVOLT_{1..4}_THR
          sync call Call_BATTERY_getBatteryVoltage: operation=BATTERY.getBatteryVoltage, timeout=0
        GarageDiagnosticsSwc_DS_DID_F09A_ReadData: symbol=GarageDiagnostics_DS_DID_F09A_ReadData
        GarageDiagnosticsSwc_DS_DID_F09F_ReadData: symbol=GarageDiagnostics_DS_DID_F09F_ReadData
        GarageDiagnosticsSwc_DS_DID_F0DF_ReadData: symbol=GarageDiagnostics_DS_DID_F0DF_ReadData
        GarageDiagnosticsSwc_DS_DID_F129_ReadData: symbol=GarageDiagnostics_DS_DID_F129_ReadData
        GarageDiagnosticsSwc_DS_DID_F198_ReadData: symbol=GarageDiagnostics_DS_DID_F198_ReadData
        GarageDiagnosticsSwc_DS_DID_F1DE_ReadData: symbol=GarageDiagnostics_DS_DID_F1DE_ReadData
        GarageDiagnosticsSwc_DS_DID_F0DF_WriteData: symbol=GarageDiagnostics_DS_DID_F0DF_WriteData
        GarageDiagnosticsSwc_DS_DID_F09A_WriteData: symbol=GarageDiagnostics_DS_DID_F09A_WriteData
        GarageDiagnosticsSwc_DS_DID_F129_WriteData: symbol=GarageDiagnostics_DS_DID_F129_WriteData
        GarageDiagnosticsSwc_DS_DID_F198_WriteData: symbol=GarageDiagnostics_DS_DID_F198_WriteData
          sync call Call_CURRENT_RSCOTSN_DATA_STORE_NVM_WriteBlock: operation=CURRENT_RSCOTSN_DATA_STORE_NVM.WriteBlock, timeout=0
          sync call Call_LAST_RSCOTSN_DATA_STORE_NVM_WriteBlock: operation=LAST_RSCOTSN_DATA_STORE_NVM.WriteBlock, timeout=0
          sync call Call_SECOND_LAST_RSCOTSN_DATA_STORE_NVM_WriteBlock: operation=SECOND_LAST_RSCOTSN_DATA_STORE_NVM.WriteBlock, timeout=0
        GarageDiagnosticsSwc_SRSN_DiagSessionChangeRationalityCheck_Indication: symbol=GarageDiagnostics_SRSN_DiagSessionChangeRationalityCheck_Indication
          data-receive-point-by-arguments:
            access R_ENG_RUN_EngineRun: accessed-variable=ENG_RUN.EngineRun
            access R_SYS_PWR_MD_SysPwrMd: accessed-variable=SYS_PWR_MD.SysPwrMd
            access R_RAW_VEH_SPD_VehicleSpeed: accessed-variable=RAW_VEH_SPD.VehicleSpeed
          parameter access CGD_VEH_SPEED_RAT_CHECK_THR: accessed-parameter=CGD_VEH_SPEED_RAT_CHECK_THR
          sync call Call_DCM_SERVICES_GetSecurityLevel: operation=DCM_SERVICES.GetSecurityLevel, timeout=0
          written-local-variables:
            access WV_SID_28_CommControlStatus: accessed-variable=SID_28_CommControlStatus
        GarageDiagnosticsSwc_SRSN_ReadDataByIdRationalityCheck_Indication: symbol=GarageDiagnostics_SRSN_ReadDataByIdRationalityCheck_Indication
        GarageDiagnosticsSwc_SRSN_RoutineControlRationalityCheck_Indication: symbol=GarageDiagnostics_SRSN_RoutineControlRationalityCheck_Indication
        GarageDiagnosticsSwc_SRSN_WriteDataByIdRationalityCheck_Indication: symbol=GarageDiagnostics_SRSN_WriteDataByIdRationalityCheck_Indication
        GarageDiagnosticsSwc_SRSN_DiagSessionChangeRationalityCheck_Confirmation: symbol=GarageDiagnostics_SRSN_DiagSessionChangeRationalityCheck_Confirmation
        GarageDiagnosticsSwc_SRSN_ReadDataByIdRationalityCheck_Confirmation: symbol=GarageDiagnostics_SRSN_ReadDataByIdRationalityCheck_Confirmation
        GarageDiagnosticsSwc_SRSN_RoutineControlRationalityCheck_Confirmation: symbol=GarageDiagnostics_SRSN_RoutineControlRationalityCheck_Confirmation
        GarageDiagnosticsSwc_SRSN_WriteDataByIdRationalityCheck_Confirmation: symbol=GarageDiagnostics_SRSN_WriteDataByIdRationalityCheck_Confirmation
        GarageDiagnosticsSwc_GenerateRandomNumber: symbol=GarageDiagnostics_GenerateRandomNumber  # Provides a random number required by SUM_SSC
        GarageDiagnosticsSwc_checkForFastShutdown: symbol=GarageDiagnostics_checkForFastShutdown  # This runnable checks whether CGD should trigger a fast shutdown (based of a XCP set attribute "RequestFastShutdown" equalling TRUE) or not.
          data-read-access:
            access R_VSPD_DATA_VehicleSpeed: accessed-variable=VSPD_DATA.VehicleSpeed
            access R_ENG_RUN_EngineRun: accessed-variable=ENG_RUN.EngineRun
          read-local-variables:
            access RV_SID_28_CommControlStatus: accessed-variable=SID_28_CommControlStatus
            access RV_XcpEnabled: accessed-variable=XcpEnabled
          sync call Call_EOL_NVM_DATA_getEppEolTestStatus: operation=EOL_NVM_DATA.getEppEolTestStatus, timeout=0
          sync call Call_GM_CGD_performFastShutdown: operation=GM_CGD.performFastShutdown, timeout=0
        GarageDiagnosticsSwc_performShutdownAction: symbol=GarageDiagnostics_performShutdownAction  # Interface that allows the client component to tell a server component that a shutdown is imminent and the server should act accordingly.
          data-send-points:
            access W_MEC_MEC: accessed-variable=MEC.MEC
          read-local-variables:
            access RV_MotorOverloadProtectionOccurred: accessed-variable=MotorOverloadProtectionOccurred
          sync call Call_MEC_DATA_STORE_NVM_WriteBlock: operation=MEC_DATA_STORE_NVM.WriteBlock, timeout=0
          sync call Call_OVLD_PROT_PAST_50_IGN_CYCLES_DATA_STORE_NVM_WriteBlock: operation=OVLD_PROT_PAST_50_IGN_CYCLES_DATA_STORE_NVM.WriteBlock, timeout=0
          sync call Call_STEERING_MOTOR_OVLD_INC_DATA_STORE_NVM_WriteBlock: operation=STEERING_MOTOR_OVLD_INC_DATA_STORE_NVM.WriteBlock, timeout=0
        GarageDiagnosticsSwc_checkEcuReset: mode-access-point=ECU_RESET.DcmEcuReset, symbol=GarageDiagnostics_checkEcuReset  # Following runnable checks if resetRequest occurs in DCM mode - switch port. If yes than is triggering appropriate process in Vehicle State SWC.
          sync call Call_CGD_resetRequest: operation=CGD.resetRequest, timeout=0
        GarageDiagnosticsSwc_provideDataToSums: symbol=GarageDiagnostics_provideDataToSums  # Simple runnable that passes data onto the RTE to be picked up by the SUM SSC.
          data-read-access:
            access R_ENG_RUN_EngineRun: accessed-variable=ENG_RUN.EngineRun
            access R_VSPD_DATA_VehicleSpeed: accessed-variable=VSPD_DATA.VehicleSpeed
          data-write-access:
            access W_SUM_SSC_PropulsionSystemActive_If_PropulsionSystemActive: accessed-variable=SUM_SSC_PropulsionSystemActive_If.PropulsionSystemActive
            access W_SUM_SSC_VehicleSpeed_If_VehicleSpeed: accessed-variable=SUM_SSC_VehicleSpeed_If.VehicleSpeed
        GarageDiagnosticsSwc_calculateTimeSinceIgnitionOn: symbol=GarageDiagnostics_calculateTimeSinceIgnitionOn  # Following runnable checks how much time EPS has been working from ingition on.
          read-local-variables:
            access RV_CalculatedTimeSinceIgnitionOn: accessed-variable=CalculatedTimeSinceIgnitionOn
          written-local-variables:
            access WV_CalculatedTimeSinceIgnitionOn: accessed-variable=CalculatedTimeSinceIgnitionOn
        GarageDiagnosticsSwc_checkSteeringMotorOverloadProtectionIncidents: symbol=GarageDiagnostics_checkSteeringMotorOverloadProtectionIncidents  # This runnable increments NVM counter to indicate if assist was reduced due to failure reasons.
          data-read-access:
            access R_ASSIST_STATES_AssistState: accessed-variable=ASSIST_STATES.AssistState
            access R_ASSIST_CAP_Capability: accessed-variable=ASSIST_CAP.Capability
          read-local-variables:
            access RV_MotorOverloadProtectionOccurred: accessed-variable=MotorOverloadProtectionOccurred
          written-local-variables:
            access WV_MotorOverloadProtectionOccurred: accessed-variable=MotorOverloadProtectionOccurred
        GarageDiagnosticsSwc_RS_RID_FF01_Start: symbol=GarageDiagnostics_RS_RID_FF01_Start
          data-receive-point-by-arguments:
            4 x access:
              R_REM_PROG_RemoteProgrammingState: accessed-variable=REM_PROG.RemoteProgrammingState
              R_RAW_VEH_SPD_VehicleSpeed: accessed-variable=RAW_VEH_SPD.VehicleSpeed
              R_ENG_RUN_EngineRun: accessed-variable=ENG_RUN.EngineRun
              R_SYS_PWR_MD_SysPwrMd: accessed-variable=SYS_PWR_MD.SysPwrMd
          read-local-variables:
            access RV_SID_28_CommControlStatus: accessed-variable=SID_28_CommControlStatus
            access RV_RemProgStateNvmJobStatus: accessed-variable=RemProgStateNvmJobStatus
          sync call Call_REM_PROG_STATE_NVM_WriteBlock: operation=REM_PROG_STATE_NVM.WriteBlock, timeout=0
          sync call Call_DCM_SERVICES_GetSecurityLevel: operation=DCM_SERVICES.GetSecurityLevel, timeout=0
        GarageDiagnosticsSwc_JobFinished_RemProgStateNvm: symbol=GarageDiagnostics_JobFinished_RemProgStateNvm
          written-local-variables:
            access WV_RemProgStateNvmJobStatus: accessed-variable=RemProgStateNvmJobStatus
      21 x swc service dependency:
        SwcNv_MecDataStoreNvm: assigned-ports=role-based-port-assignment={port-prototype=MEC_DATA_STORE_NVM, role=MecDataStoreNvm}
          assigned-datas:
            role=ramBlock, used-data-element=MecDataStoreNvm
            role=defaultValue, used-parameter-element=MecDataStoreNvm_DEFAULT_VALUE
          service-needs:
            nv block needs SwcNv_MecDataStoreNvm: calc-ram-block-crc=true, check-static-block-id=false, n-rom-blocks=1, ram-block-status-control=NV-RAM-MANAGER, readonly=false, reliability=ERROR-DETECTION, resistant-to-changed-sw=true, restore-at-start=true, store-at-shutdown=false, store-cyclic=false, store-emergency=false, store-immediate=true, use-auto-validation-at-shut-down=false, use-crc-comp-mechanism=true, write-only-once=false, write-verification=false
        SwcNv_SbaTicketDataStoreNvm: assigned-ports=role-based-port-assignment={port-prototype=SBAT_DATA_STORE_NVM, role=SbaTicketDataStoreNvm}
          assigned-datas:
            role=ramBlock, used-data-element=SbaTicketDataStoreNvm
            role=defaultValue, used-parameter-element=SbaTicketDataStoreNvm_DEFAULT_VALUE
          service-needs:
            nv block needs SwcNv_SbaTicketDataStoreNvm: calc-ram-block-crc=true, check-static-block-id=false, n-rom-blocks=1, ram-block-status-control=NV-RAM-MANAGER, readonly=false, reliability=ERROR-DETECTION, resistant-to-changed-sw=true, restore-at-start=true, store-at-shutdown=false, store-cyclic=false, store-emergency=false, store-immediate=true, use-auto-validation-at-shut-down=false, use-crc-comp-mechanism=true, write-only-once=false, write-verification=false
        SwcNv_ProgramDateDataStoreNvm: assigned-ports=role-based-port-assignment={port-prototype=PROG_DATE_DATA_STORE_NVM, role=ProgramDateDataStoreNvm}
          assigned-datas:
            role=ramBlock, used-data-element=ProgramDateDataStoreNvm
            role=defaultValue, used-parameter-element=ProgramDateDataStoreNvm_DEFAULT_VALUE
          service-needs:
            nv block needs SwcNv_ProgramDateDataStoreNvm: calc-ram-block-crc=true, check-static-block-id=false, n-rom-blocks=1, ram-block-status-control=NV-RAM-MANAGER, readonly=false, reliability=ERROR-DETECTION, resistant-to-changed-sw=true, restore-at-start=true, store-at-shutdown=false, store-cyclic=false, store-emergency=false, store-immediate=true, use-auto-validation-at-shut-down=false, use-crc-comp-mechanism=true, write-only-once=false, write-verification=false
        SwcNv_VppsDataStoreNvm: assigned-ports=role-based-port-assignment={port-prototype=VPPS_DATA_STORE_NVM, role=VppsDataStoreNvm}
          assigned-datas:
            role=ramBlock, used-data-element=VppsDataStoreNvm
            role=defaultValue, used-parameter-element=VppsDataStoreNvm_DEFAULT_VALUE
          service-needs:
            nv block needs SwcNv_VppsDataStoreNvm: calc-ram-block-crc=true, check-static-block-id=false, n-rom-blocks=1, ram-block-status-control=NV-RAM-MANAGER, readonly=false, reliability=ERROR-DETECTION, resistant-to-changed-sw=true, restore-at-start=true, store-at-shutdown=false, store-cyclic=false, store-emergency=false, store-immediate=true, use-auto-validation-at-shut-down=false, use-crc-comp-mechanism=true, write-only-once=false, write-verification=false
        SwcNv_DunsDataStoreNvm: assigned-ports=role-based-port-assignment={port-prototype=DUNS_DATA_STORE_NVM, role=DunsDataStoreNvm}
          assigned-datas:
            role=ramBlock, used-data-element=DunsDataStoreNvm
            role=defaultValue, used-parameter-element=DunsDataStoreNvm_DEFAULT_VALUE
          service-needs:
            nv block needs SwcNv_DunsDataStoreNvm: calc-ram-block-crc=true, check-static-block-id=false, n-rom-blocks=1, ram-block-status-control=NV-RAM-MANAGER, readonly=false, reliability=ERROR-DETECTION, resistant-to-changed-sw=true, restore-at-start=true, store-at-shutdown=false, store-cyclic=false, store-emergency=false, store-immediate=true, use-auto-validation-at-shut-down=false, use-crc-comp-mechanism=true, write-only-once=false, write-verification=false
        SwcNv_MtcDataStoreNvm: assigned-ports=role-based-port-assignment={port-prototype=MTC_DATA_STORE_NVM, role=MtcDataStoreNvm}
          assigned-datas:
            role=ramBlock, used-data-element=MtcDataStoreNvm
            role=defaultValue, used-parameter-element=MtcDataStoreNvm_DEFAULT_VALUE
          service-needs:
            nv block needs SwcNv_MtcDataStoreNvm: calc-ram-block-crc=true, check-static-block-id=false, n-rom-blocks=1, ram-block-status-control=NV-RAM-MANAGER, readonly=false, reliability=ERROR-DETECTION, resistant-to-changed-sw=true, restore-at-start=true, store-at-shutdown=false, store-cyclic=false, store-emergency=false, store-immediate=true, use-auto-validation-at-shut-down=false, use-crc-comp-mechanism=true, write-only-once=false, write-verification=false
        SwcNv_InitialReflashFlagStoreNvm: assigned-ports=role-based-port-assignment={port-prototype=REFLASH_FLAG_STORE_NVM, role=InitialReflashFlagStoreNvm}
          assigned-datas:
            role=ramBlock, used-data-element=InitialReflashFlagStoreNvm
            role=defaultValue, used-parameter-element=InitialReflashFlagStoreNvm_DEFAULT_VALUE
          service-needs:
            nv block needs SwcNv_InitialReflashFlagStoreNvm: calc-ram-block-crc=true, check-static-block-id=false, n-rom-blocks=1, ram-block-status-control=NV-RAM-MANAGER, readonly=false, reliability=ERROR-DETECTION, resistant-to-changed-sw=true, restore-at-start=true, store-at-shutdown=false, store-cyclic=false, store-emergency=false, store-immediate=true, use-auto-validation-at-shut-down=false, use-crc-comp-mechanism=true, write-only-once=false, write-verification=false
        SwcNv_EmpnDataStoreNvm: assigned-ports=role-based-port-assignment={port-prototype=EMPN_DATA_STORE_NVM, role=EmpnDataStoreNvm}
          assigned-datas:
            role=ramBlock, used-data-element=EmpnDataStoreNvm
            role=defaultValue, used-parameter-element=EmpnDataStoreNvm_DEFAULT_VALUE
          service-needs:
            nv block needs SwcNv_EmpnDataStoreNvm: calc-ram-block-crc=true, check-static-block-id=false, n-rom-blocks=1, ram-block-status-control=NV-RAM-MANAGER, readonly=false, reliability=ERROR-DETECTION, resistant-to-changed-sw=true, restore-at-start=true, store-at-shutdown=false, store-cyclic=false, store-emergency=false, store-immediate=true, use-auto-validation-at-shut-down=false, use-crc-comp-mechanism=true, write-only-once=false, write-verification=false
        SwcNv_EmpnacDataStoreNvm: assigned-ports=role-based-port-assignment={port-prototype=EMPNAC_DATA_STORE_NVM, role=EmpnacDataStoreNvm}
          assigned-datas:
            role=ramBlock, used-data-element=EmpnacDataStoreNvm
            role=defaultValue, used-parameter-element=EmpnacDataStoreNvm_DEFAULT_VALUE
          service-needs:
            nv block needs SwcNv_EmpnacDataStoreNvm: calc-ram-block-crc=true, check-static-block-id=false, n-rom-blocks=1, ram-block-status-control=NV-RAM-MANAGER, readonly=false, reliability=ERROR-DETECTION, resistant-to-changed-sw=true, restore-at-start=true, store-at-shutdown=false, store-cyclic=false, store-emergency=false, store-immediate=true, use-auto-validation-at-shut-down=false, use-crc-comp-mechanism=true, write-only-once=false, write-verification=false
        SwcNv_MacBypassDataStoreNvm: assigned-ports=role-based-port-assignment={port-prototype=MAC_BYPASS_DATA_STORE_NVM, role=MacBypassDataStoreNvm}
          assigned-datas:
            role=ramBlock, used-data-element=MacBypassDataStoreNvm
            role=defaultValue, used-parameter-element=MacBypassDataStoreNvm_DEFAULT_VALUE
          service-needs:
            nv block needs SwcNv_MacBypassDataStoreNvm: calc-ram-block-crc=true, check-static-block-id=false, n-rom-blocks=1, ram-block-status-control=NV-RAM-MANAGER, readonly=false, reliability=ERROR-DETECTION, resistant-to-changed-sw=true, restore-at-start=true, store-at-shutdown=false, store-cyclic=false, store-emergency=false, store-immediate=true, use-auto-validation-at-shut-down=false, use-crc-comp-mechanism=true, write-only-once=false, write-verification=false
        SwcNv_SaBypassDataStoreNvm: assigned-ports=role-based-port-assignment={port-prototype=SA_BYPASS_DATA_STORE_NVM, role=SaBypassDataStoreNvm}
          assigned-datas:
            role=ramBlock, used-data-element=SaBypassDataStoreNvm
            role=defaultValue, used-parameter-element=SaBypassDataStoreNvm_DEFAULT_VALUE
          service-needs:
            nv block needs SwcNv_SaBypassDataStoreNvm: calc-ram-block-crc=true, check-static-block-id=false, n-rom-blocks=1, ram-block-status-control=NV-RAM-MANAGER, readonly=false, reliability=ERROR-DETECTION, resistant-to-changed-sw=true, restore-at-start=true, store-at-shutdown=false, store-cyclic=false, store-emergency=false, store-immediate=true, use-auto-validation-at-shut-down=false, use-crc-comp-mechanism=true, write-only-once=false, write-verification=false
        SwcNv_CurrentRSCOTSNDataStoreNvm: assigned-ports=role-based-port-assignment={port-prototype=CURRENT_RSCOTSN_DATA_STORE_NVM, role=CurrentRSCOTSNDataStoreNvm}
          assigned-datas:
            role=ramBlock, used-data-element=CurrentRSCOTSNDataStoreNvm
            role=defaultValue, used-parameter-element=CurrentRSCOTSNDataStoreNvm_DEFAULT_VALUE
          service-needs:
            nv block needs SwcNv_CurrentRSCOTSNDataStoreNvm: calc-ram-block-crc=true, check-static-block-id=false, n-rom-blocks=1, ram-block-status-control=NV-RAM-MANAGER, readonly=false, reliability=ERROR-DETECTION, resistant-to-changed-sw=true, restore-at-start=true, store-at-shutdown=false, store-cyclic=false, store-emergency=false, store-immediate=true, use-auto-validation-at-shut-down=false, use-crc-comp-mechanism=true, write-only-once=false, write-verification=false
        SwcNv_SecondLastRSCOTSNDataStoreNvm: assigned-ports=role-based-port-assignment={port-prototype=SECOND_LAST_RSCOTSN_DATA_STORE_NVM, role=SecondLastRSCOTSNDataStoreNvm}
          assigned-datas:
            role=ramBlock, used-data-element=SecondLastRSCOTSNDataStoreNvm
            role=defaultValue, used-parameter-element=SecondLastRSCOTSNDataStoreNvm_DEFAULT_VALUE
          service-needs:
            nv block needs SwcNv_SecondLastRSCOTSNDataStoreNvm: calc-ram-block-crc=true, check-static-block-id=false, n-rom-blocks=1, ram-block-status-control=NV-RAM-MANAGER, readonly=false, reliability=ERROR-DETECTION, resistant-to-changed-sw=true, restore-at-start=true, store-at-shutdown=false, store-cyclic=false, store-emergency=false, store-immediate=true, use-auto-validation-at-shut-down=false, use-crc-comp-mechanism=true, write-only-once=false, write-verification=false
        SwcNv_LastRSCOTSNDataStoreNvm: assigned-ports=role-based-port-assignment={port-prototype=LAST_RSCOTSN_DATA_STORE_NVM, role=LastRSCOTSNDataStoreNvm}
          assigned-datas:
            role=ramBlock, used-data-element=LastRSCOTSNDataStoreNvm
            role=defaultValue, used-parameter-element=LastRSCOTSNDataStoreNvm_DEFAULT_VALUE
          service-needs:
            nv block needs SwcNv_LastRSCOTSNDataStoreNvm: calc-ram-block-crc=true, check-static-block-id=false, n-rom-blocks=1, ram-block-status-control=NV-RAM-MANAGER, readonly=false, reliability=ERROR-DETECTION, resistant-to-changed-sw=true, restore-at-start=true, store-at-shutdown=false, store-cyclic=false, store-emergency=false, store-immediate=true, use-auto-validation-at-shut-down=false, use-crc-comp-mechanism=true, write-only-once=false, write-verification=false
        SwcNv_StrgMotorOvldProtIncDataStoreNvm: assigned-ports=role-based-port-assignment={port-prototype=STEERING_MOTOR_OVLD_INC_DATA_STORE_NVM, role=StrgMotorOvldProtIncDataStoreNvm}
          assigned-datas:
            role=ramBlock, used-data-element=StrgMotorOvldProtIncDataStoreNvm
            role=defaultValue, used-parameter-element=StrgMotorOvldProtIncDataStoreNvm_DEFAULT_VALUE
          service-needs:
            nv block needs SwcNv_StrgMotorOvldProtIncDataStoreNvm: calc-ram-block-crc=true, check-static-block-id=false, n-rom-blocks=1, ram-block-status-control=NV-RAM-MANAGER, readonly=false, reliability=ERROR-DETECTION, resistant-to-changed-sw=true, restore-at-start=true, store-at-shutdown=false, store-cyclic=false, store-emergency=false, store-immediate=true, use-auto-validation-at-shut-down=false, use-crc-comp-mechanism=true, write-only-once=false, write-verification=false
        SwcNv_OvldProtPast50IgnCyclesDataStoreNvm: assigned-ports=role-based-port-assignment={port-prototype=OVLD_PROT_PAST_50_IGN_CYCLES_DATA_STORE_NVM, role=OvldProtPast50IgnCyclesDataStoreNvm}
          assigned-datas:
            role=ramBlock, used-data-element=OvldProtPast50IgnCyclesDataStoreNvm
            role=defaultValue, used-parameter-element=OvldProtPast50IgnCyclesDataStoreNvm_DEFAULT_VALUE
          service-needs:
            nv block needs SwcNv_OvldProtPast50IgnCyclesDataStoreNvm: calc-ram-block-crc=true, check-static-block-id=false, n-rom-blocks=1, ram-block-status-control=NV-RAM-MANAGER, readonly=false, reliability=ERROR-DETECTION, resistant-to-changed-sw=true, restore-at-start=true, store-at-shutdown=false, store-cyclic=false, store-emergency=false, store-immediate=true, use-auto-validation-at-shut-down=false, use-crc-comp-mechanism=true, write-only-once=false, write-verification=false
        SwcNv_RemProgStateNvm: assigned-ports=role-based-port-assignment={port-prototype=REM_PROG_STATE_NVM, role=NvMService}
          assigned-datas:
            role=ramBlock, used-data-element=RemProgStateNvm
            role=defaultValue, used-parameter-element=RemProgStateNvm_DEFAULT_VALUE
          service-needs:
            nv block needs SwcNv_RemProgStateNvm: calc-ram-block-crc=true, check-static-block-id=false, n-rom-blocks=1, ram-block-status-control=NV-RAM-MANAGER, readonly=false, reliability=ERROR-DETECTION, resistant-to-changed-sw=true, restore-at-start=true, store-at-shutdown=false, store-cyclic=false, store-emergency=false, store-immediate=true, use-auto-validation-at-shut-down=false, use-crc-comp-mechanism=true, write-only-once=false, write-verification=false
        Monitor_VIN_NOT_PROGRAMMED: assigned-ports=role-based-port-assignment={port-prototype=VIN_NOT_PROGRAMMED_MON, role=DiagnosticMonitor}
          service-needs:
            diagnostic event needs EventNeed_VIN_NOT_PROGRAMMED
        Info_VIN_NOT_PROGRAMMED: assigned-ports=role-based-port-assignment={port-prototype=VIN_NOT_PROGRAMMED_INFO, role=DiagnosticInfo}
          service-needs:
            diagnostic event info needs InfoNeed_VIN_NOT_PROGRAMMED
        Monitor_EOL_CALIBRATION_NOT_FLASHED: assigned-ports=role-based-port-assignment={port-prototype=EOL_CALIBRATION_NOT_FLASHED_MON, role=DiagnosticMonitor}
          service-needs:
            diagnostic event needs EventNeed_EOL_CALIBRATION_NOT_FLASHED
        Info_EOL_CALIBRATION_NOT_FLASHED: assigned-ports=role-based-port-assignment={port-prototype=EOL_CALIBRATION_NOT_FLASHED_INFO, role=DiagnosticInfo}
          service-needs:
            diagnostic event info needs InfoNeed_EOL_CALIBRATION_NOT_FLASHED
  impl type tMecDataStoreNvm: category=STRUCTURE
    element MecNvRamBlock: implementation-data-type=tMecNvRamBlockSize
  constant specification GarageDiagnosticsSwc_MecDataStoreNvm_Init: value-spec={short-label=GarageDiagnosticsSwc_MecDataStoreNvm_Init, fields=8 x 254}
  impl type tSbaTicketDataStoreNvm: category=STRUCTURE
    element SbaTicketNvRamBlock: implementation-data-type=tSBINvmDataBlock
  constant specification GarageDiagnosticsSwc_SbaTicketDataStoreNvm_Init: value-spec={short-label=GarageDiagnosticsSwc_SbaTicketDataStoreNvm_Init, fields={short-label=SbaTicketDataStoreNvm_SbaTicketNvRamBlock_Init, fields=[0, 822 x 255]}}
  impl type tProgramDateDataStoreNvm: category=STRUCTURE
    element ProgDateDateNvRamBlock: implementation-data-type=tProgDateNvmDataBlock
  constant specification GarageDiagnosticsSwc_ProgramDateDataStoreNvm_Init: value-spec={short-label=GarageDiagnosticsSwc_ProgramDateDataStoreNvm_Init, fields=[255, 255, 255, 255]}
  impl type tVppsDataStoreNvm: category=STRUCTURE
    element VppsValue: implementation-data-type=tVppsNvRamBlockSize
  constant specification GarageDiagnosticsSwc_VppsDataStoreNvm_Init: value-spec={short-label=GarageDiagnosticsSwc_VppsDataStoreNvm_Init, fields=[0x32, 0x31, 0x34, 0x39, 0x37, 0x30, 0x30, 0x30, 0x30, 0x30, 0x30, 0x30, 0x30, 0x58]}
  impl type tDunsDataStoreNvm: category=STRUCTURE
    element DunsValue: implementation-data-type=tDunsNvRamBlockSize
  constant specification GarageDiagnosticsSwc_DunsDataStoreNvm_Init: value-spec={short-label=GarageDiagnosticsSwc_DunsDataStoreNvm_Init, fields=[57, 49, 52, 54, 54, 54, 53, 53, 50]}
  impl type tMtcDataStoreNvm: category=STRUCTURE
    element MtcValue: implementation-data-type=tMtcNvRamBlockSize
  constant specification GarageDiagnosticsSwc_MtcDataStoreNvm_Init: value-spec={short-label=GarageDiagnosticsSwc_MtcDataStoreNvm_Init, fields=16 x 88}
  impl type tInitialReflashFlagStoreNvm: category=STRUCTURE
    element InitialReflashFlag: implementation-data-type=UInt8
  constant specification GarageDiagnosticsSwc_InitialReflashFlagStoreNvm_Init: value-spec={short-label=GarageDiagnosticsSwc_InitialReflashFlagStoreNvm_Init, fields=0}
  impl type tEmpnDataStoreNvm: category=STRUCTURE
    element EmpnValue: implementation-data-type=tGM_EmpnNvRamBlockSize
    element EmpnProvided: implementation-data-type=tGM_NvmProvided
  constant specification GarageDiagnosticsSwc_EmpnDataStoreNvm_Init: value-spec={short-label=GarageDiagnosticsSwc_EmpnDataStoreNvm_Init, fields=[[0, 0, 0, 0], 0]}
  impl type tEmpnacDataStoreNvm: category=STRUCTURE
    element EmpnacValue: implementation-data-type=tGM_EmpnacNvRamBlockSize
    element EmpnacProvided: implementation-data-type=tGM_NvmProvided
  constant specification GarageDiagnosticsSwc_EmpnacDataStoreNvm_Init: value-spec={short-label=GarageDiagnosticsSwc_EmpnacDataStoreNvm_Init, fields=[[0, 0], 0]}
  impl type tMacBypassDataStoreNvm: category=STRUCTURE
    element MacBypassValue: implementation-data-type=tGM_MacBypassNvRamBlockSize
  constant specification GarageDiagnosticsSwc_MacBypassDataStoreNvm_Init: value-spec={short-label=GarageDiagnosticsSwc_MacBypassDataStoreNvm_Init, fields=0}
  impl type tSaBypassDataStoreNvm: category=STRUCTURE
    element SaBypassValue: implementation-data-type=tGM_SaBypassNvRamBlockSize
  constant specification GarageDiagnosticsSwc_SaBypassDataStoreNvm_Init: value-spec={short-label=GarageDiagnosticsSwc_SaBypassDataStoreNvm_Init, fields=1}
  impl type tCurrentRSCOTSNDataStoreNvm: category=STRUCTURE
    element CurrentRSCOTSNValue: implementation-data-type=tCurrentRSCOTSN_NvRamBlockSize
  constant specification GarageDiagnosticsSwc_CurrentRSCOTSNDataStoreNvm_Init: value-spec={short-label=GarageDiagnosticsSwc_CurrentRSCOTSNDataStoreNvm_Init, fields=10 x 0}
  impl type tSecondLastRSCOTSNDataStoreNvm: category=STRUCTURE
    element SecondLastRSCOTSNValue: implementation-data-type=tSecondLastRSCOTSN_NvRamBlockSize
  constant specification GarageDiagnosticsSwc_SecondLastRSCOTSNDataStoreNvm_Init: value-spec={short-label=GarageDiagnosticsSwc_SecondLastRSCOTSNDataStoreNvm_Init, fields=10 x 0}
  impl type tLastRSCOTSNDataStoreNvm: category=STRUCTURE
    element LastRSCOTSNValue: implementation-data-type=tLastRSCOTSN_NvRamBlockSize
  constant specification GarageDiagnosticsSwc_LastRSCOTSNDataStoreNvm_Init: value-spec={short-label=GarageDiagnosticsSwc_LastRSCOTSNDataStoreNvm_Init, fields=10 x 0}
  impl type tStrgMotorOvldProtIncDataStoreNvm: category=STRUCTURE
    element StrgMotorOvldProtIncValue: implementation-data-type=tStrgMotorOvldProtInc_NvRamBlockSize
  constant specification GarageDiagnosticsSwc_StrgMotorOvldProtIncDataStoreNvm_Init: value-spec={short-label=GarageDiagnosticsSwc_StrgMotorOvldProtIncDataStoreNvm_Init, fields=0x00}
  impl type tOvldProtPast50IgnCyclesDataStoreNvm: category=STRUCTURE
    element OvldProtPast50IgnCyclesValue: implementation-data-type=tOvldProtPast50IgnCycles_NvRamBlockSize
  constant specification GarageDiagnosticsSwc_OvldProtPast50IgnCyclesDataStoreNvm_Init: value-spec={short-label=GarageDiagnosticsSwc_OvldProtPast50IgnCyclesDataStoreNvm_Init, fields=0x00}
  impl type tRemProgStateNvm: category=STRUCTURE
    element RemProgState: implementation-data-type=Boolean
  16 x constant specification:
    GarageDiagnosticsSwc_RemProgStateNvm_Init: value-spec={short-label=GarageDiagnosticsSwc_RemProgStateNvm_Init, fields=0}
    GarageDiagnosticsSwc_RoutineIdentifier_Init: value-spec=0
    GarageDiagnosticsSwc_DeviceLimitsExceededCode_Init: value-spec=0
    GarageDiagnosticsSwc_CalculatedTimeSinceIgnitionOn_Init: value-spec=0
    GarageDiagnosticsSwc_MotorOverloadProtectionOccurred_Init: value-spec=0
    GarageDiagnosticsSwc_SID_28_CommControlStatus_Init: value-spec=0
    GarageDiagnosticsSwc_RemProgStateNvmJobStatus_Init: value-spec=0
    GarageDiagnosticsSwc_XcpEnabled_Init: value-spec=0
    FeatureTune_APA_FEATURE_ENABLED_FLAG_Init: value-spec=1
    VehicleTune_CGD_VEH_SPEED_RAT_CHECK_THR_Init: value-spec=10.0
    VehicleTune_CGD_OVERVOLT_THR_Init: value-spec=16.0
    VehicleTune_CGD_UNDERVOLT_1_THR_Init: value-spec=10.0
    VehicleTune_CGD_UNDERVOLT_2_THR_Init: value-spec=9.0
    VehicleTune_CGD_UNDERVOLT_3_THR_Init: value-spec=6.5
    VehicleTune_CGD_UNDERVOLT_4_THR_Init: value-spec=5.9
    VehicleTune_XCP_TIMEOUT_Init: value-spec=0.5
package /GeneralMotorsPkg/GeneralMotorsArchitecturePkg/GeneralMotorsVehicleAbstractionPkg/ApplicationTypesPkg
  17 x application record data type, all with category=STRUCTURE:
    tMecDataStoreNvm
      application record element MecNvRamBlock: category=ARRAY, type=tMecNvRamBlockSize
    tSbaTicketDataStoreNvm
      application record element SbaTicketNvRamBlock: category=STRUCTURE, type=tSBINvmDataBlock
    tProgramDateDataStoreNvm
      application record element ProgDateDateNvRamBlock: category=ARRAY, type=tProgDateNvmDataBlock
    tVppsDataStoreNvm  # NVM storage block for Compressed Vehicle Partitioning and Product Structure (VPPS)
      application record element VppsValue: category=ARRAY, type=tVppsNvRamBlockSize
    tDunsDataStoreNvm  # NVM storage block for Data Universal Numbering System Identification (DUNS)
      application record element DunsValue: category=ARRAY, type=tDunsNvRamBlockSize
    tMtcDataStoreNvm  # NVM storage block for ManufacturingTraceabilityCharacters (MTC)
      application record element MtcValue: category=ARRAY, type=tMtcNvRamBlockSize
    tInitialReflashFlagStoreNvm  # NVM store for the InitialReflashFlag that is used by the SUM_SSC to check if the NVM storage of the Anti-Replay Counters was successful or not.
      application record element InitialReflashFlag: category=VALUE, type=UInt8
    tEmpnDataStoreNvm  # NVM storage block for End Model Part Number (EMPN)
      application record element EmpnValue: category=ARRAY, type=tGM_EmpnNvRamBlockSize
      application record element EmpnProvided: category=VALUE, type=tGM_NvmProvided
    tEmpnacDataStoreNvm  # NVM storage block for End Model Part Number Alpha Code (EMPNAC)
      application record element EmpnacValue: category=ARRAY, type=tGM_EmpnacNvRamBlockSize
      application record element EmpnacProvided: category=VALUE, type=tGM_NvmProvided
    tMacBypassDataStoreNvm  # NVM storage block for Message Authentication Code (MAC) Bypass
      application record element MacBypassValue: category=VALUE, type=tGM_MacBypassNvRamBlockSize
    tSaBypassDataStoreNvm  # NVM storage block for Security Access (SA) Bypass
      application record element SaBypassValue: category=VALUE, type=tGM_SaBypassNvRamBlockSize
    tCurrentRSCOTSNDataStoreNvm  # NVM storage block for Current Stored Repair Shop Code Or Tester Serial Numbers (RSCOTSN)
      application record element CurrentRSCOTSNValue: category=ARRAY, type=tCurrentRSCOTSN_NvRamBlockSize
    tSecondLastRSCOTSNDataStoreNvm  # NVM block intended for storing Second Last Stored Repair Shop Code Or Tester Serial Numbers (RSCOTSN)
      application record element SecondLastRSCOTSNValue: category=ARRAY, type=tSecondLastRSCOTSN_NvRamBlockSize
    tLastRSCOTSNDataStoreNvm  # NVM storage block for Last Stored Repair Shop Code Or Tester Serial Numbers (RSCOTSN)
      application record element LastRSCOTSNValue: category=ARRAY, type=tLastRSCOTSN_NvRamBlockSize
    tStrgMotorOvldProtIncDataStoreNvm  # Counter to be incremented each time when the EPS enters into reduced performance mode.
      application record element StrgMotorOvldProtIncValue: category=VALUE, type=tStrgMotorOvldProtInc_NvRamBlockSize
    tOvldProtPast50IgnCyclesDataStoreNvm  # Counter which is incremented if during active journey EPS didn't entered into reduced system performance mode. This value is incremented at every shutdown and saved into NVM. When reaches 50 value it's reset to default value 0.
      application record element OvldProtPast50IgnCyclesValue: category=VALUE, type=tOvldProtPast50IgnCycles_NvRamBlockSize
    tRemProgStateNvm  # NVM data block used to store the Remote Programming State.
      application record element RemProgState: category=VALUE, type=Boolean
package /GeneralMotorsPkg/GeneralMotorsArchitecturePkg/GeneralMotorsTypes
  unit RevsPerMin_Unit: display-name=rpm
  6 x impl type:
    RevsPerMin: implementation-data-type=Float32
    tEngineSpeed: category=STRUCTURE
      element Value: implementation-data-type=RevsPerMin
      element Qf: implementation-data-type=tQualityFactor
    tPowertrainCrankActiveData: category=STRUCTURE
      element Value: implementation-data-type=Boolean
      element Qf: implementation-data-type=tQualityFactor
    tEngine12VSMCmdOnData: category=STRUCTURE
      element Value: implementation-data-type=Boolean
      element Qf: implementation-data-type=tQualityFactor
    tSystemPowerMode: implementation-data-type=SysPwrMd_ImpType
    tSysPwrMd: category=STRUCTURE
      element Value: implementation-data-type=tSystemPowerMode
      element Qf: implementation-data-type=tQualityFactor
  compu method tPamState_Compu: 0=PA_TEMP_INHIBITED, 1=PA_AVAILABLE_FOR_CONTROL, 2=PA_ACTIVE, 3=PA_PERMANENTLY_FAILED
  23 x impl type:
    tPamState: category=VALUE, base-type=sint32, compu-method=tPamState_Compu
    tRemoteProgrammingState: category=STRUCTURE
      element Value: implementation-data-type=Boolean
      element Qf: implementation-data-type=tQualityFactor
    tStrWhAngGrd: implementation-data-type=StrWhAngGrd_ImpType
    tStrWhAngSenCalStat: implementation-data-type=StrWhlAngSenCalStat_ImpType
    tStrWhAngMsk: implementation-data-type=StrWhAngMsk_ImpType
    tStrWhAng: implementation-data-type=StrWhAng_ImpType
    tMecNvRamBlockSize: category=ARRAY
      element Element: array-size=8, array-size-semantics=FIXED-SIZE, implementation-data-type=UInt8
    tSbaTicketNvRamBlockSize: category=ARRAY
      element Element: array-size=822, array-size-semantics=FIXED-SIZE, implementation-data-type=UInt8
    tSBINvmDataBlock: category=STRUCTURE
      element SBATValidFlag: implementation-data-type=Boolean
      element SBATicket: implementation-data-type=tSbaTicketNvRamBlockSize
    tProgDateNvmDataBlock: category=ARRAY
      element Element: array-size=4, array-size-semantics=FIXED-SIZE, implementation-data-type=UInt8
    tVppsNvRamBlockSize: category=ARRAY
      element Element: array-size=14, array-size-semantics=FIXED-SIZE, implementation-data-type=UInt8
    tDunsNvRamBlockSize: category=ARRAY
      element Element: array-size=9, array-size-semantics=FIXED-SIZE, implementation-data-type=UInt8
    tMtcNvRamBlockSize: category=ARRAY
      element Element: array-size=16, array-size-semantics=FIXED-SIZE, implementation-data-type=UInt8
    tGM_EmpnNvRamBlockSize: category=ARRAY
      element Element: array-size=4, array-size-semantics=FIXED-SIZE, implementation-data-type=UInt8
    tGM_NvmProvided: implementation-data-type=UInt8
    tGM_EmpnacNvRamBlockSize: category=ARRAY
      element Element: array-size=2, array-size-semantics=FIXED-SIZE, implementation-data-type=UInt8
    tGM_MacBypassNvRamBlockSize: implementation-data-type=Boolean
    tGM_SaBypassNvRamBlockSize: implementation-data-type=Boolean
    tCurrentRSCOTSN_NvRamBlockSize: category=ARRAY
      element Element: array-size=10, array-size-semantics=FIXED-SIZE, implementation-data-type=UInt8
    tSecondLastRSCOTSN_NvRamBlockSize: category=ARRAY
      element Element: array-size=10, array-size-semantics=FIXED-SIZE, implementation-data-type=UInt8
    tLastRSCOTSN_NvRamBlockSize: category=ARRAY
      element Element: array-size=10, array-size-semantics=FIXED-SIZE, implementation-data-type=UInt8
    tStrgMotorOvldProtInc_NvRamBlockSize: implementation-data-type=UInt16
    tOvldProtPast50IgnCycles_NvRamBlockSize: implementation-data-type=UInt8
  impl type tCommControlStatusSID28: category=VALUE, base-type=sint32, compu {0=COMM_CONTROL_ENABLED_SID_0x28, 1=COMM_CONTROL_DISABLED_SID_0x28}
  impl type tCgdNvmJobStatus: category=VALUE, base-type=sint32, compu {0=NVM_JOB_INCOMPLETE, 1=NVM_JOB_COMPLETE, 2=NVM_JOB_FAILED}
package /GeneralMotorsPkg/GeneralMotorsArchitecturePkg/GeneralMotorsTypes/ApplicationTypesPkg
  app type RevsPerMin: category=VALUE, compu {phys=raw for raw -INF..INF; unit rpm}, unit=rpm
  application record data type tEngineSpeed: category=STRUCTURE
    application record element Value: category=VALUE, type=RevsPerMin
    application record element Qf: category=VALUE, type=tQualityFactor
  application record data type tPowertrainCrankActiveData: category=STRUCTURE
    application record element Value: category=VALUE, type=Boolean
    application record element Qf: category=VALUE, type=tQualityFactor
  application record data type tEngine12VSMCmdOnData: category=STRUCTURE
    application record element Value: category=VALUE, type=Boolean
    application record element Qf: category=VALUE, type=tQualityFactor
  app type tSystemPowerMode: category=VALUE  # SysPwrMd_Crank_Request - Crank Request SysPwrMd_Run - SysPwrMd_Run SysPwrMd_Off - SysPwrMd_Off SysPwrMd_Accessory - SysPwrMd_Accessory
  application record data type tSysPwrMd: category=STRUCTURE
    application record element Value: category=VALUE, type=tSystemPowerMode
    application record element Qf: category=VALUE, type=tQualityFactor
  app type tPamState: category=VALUE, base-type=sint32, compu-method=tPamState_Compu  # The state determined by the Park Assist Manager
  application record data type tRemoteProgrammingState: category=STRUCTURE  # Type used to pass the Remote Programming State, + a QF to indicate if the messages are being received.
    application record element Value: category=VALUE, type=Boolean
    application record element Qf: category=VALUE, type=tQualityFactor
  4 x app type, all with category=VALUE:
    tStrWhAngGrd  # Steering Wheel Angle Gradient
    tStrWhAngSenCalStat  # StrWhlAngSenCalStat_Unknown - StrWhlAngSenCalStat_Unknown StrWhlAngSenCalStat_Calibrated - StrWhlAngSenCalStat_Calibrated StrWhlAngSenCalStat_Estimated - StrWhlAngSenCalStat_Estimated
    tStrWhAngMsk  # StrWhAngMsk_Use_Data - Use Data StrWhAngMsk_Don_t_Use_Data - Don't Use Data
    tStrWhAng  # Steering Wheel Angle
  application array data type tMecNvRamBlockSize: category=ARRAY  # Size of the NVM storage block for MEC
    element Element: category=VALUE, type=UInt8, array-size-semantics=FIXED-SIZE, max-number-of-elements=8
  application array data type tSbaTicketNvRamBlockSize: category=ARRAY  # Size of the NVM storage block for SBA Ticket
    element Element: category=VALUE, type=UInt8, array-size-semantics=FIXED-SIZE, max-number-of-elements=822
  application record data type tSBINvmDataBlock: category=STRUCTURE
    application record element SBATValidFlag: category=VALUE, type=Boolean
    application record element SBATicket: category=ARRAY, type=tSbaTicketNvRamBlockSize
  5 x application array data type, all with category=ARRAY:
    tProgDateNvmDataBlock  # Size of the NVM storage block for Program Date
      element Element: category=VALUE, type=UInt8, array-size-semantics=FIXED-SIZE, max-number-of-elements=4
    tVppsNvRamBlockSize  # Size of the NVM storage block for Compressed Vehicle Partitioning and Product Structure (VPPS)
      element Element: category=VALUE, type=UInt8, array-size-semantics=FIXED-SIZE, max-number-of-elements=14
    tDunsNvRamBlockSize  # Size of the NVM storage block for Data Universal Numbering System Identification (DUNS)
      element Element: category=VALUE, type=UInt8, array-size-semantics=FIXED-SIZE, max-number-of-elements=9
    tMtcNvRamBlockSize  # Size of the NVM storage block for ManufacturingTraceabilityCharacters (MTC)
      element Element: category=VALUE, type=UInt8, array-size-semantics=FIXED-SIZE, max-number-of-elements=16
    tGM_EmpnNvRamBlockSize  # NVM data size for End Model Part Number (EMPN)
      element Element: category=VALUE, type=UInt8, array-size-semantics=FIXED-SIZE, max-number-of-elements=4
  app type tGM_NvmProvided: category=VALUE  # Indication that the NVM has been provided in response to request
  application array data type tGM_EmpnacNvRamBlockSize: category=ARRAY  # NVM data size for End Model Part Number Alpha Code (EMPNAC)
    element Element: category=VALUE, type=UInt8, array-size-semantics=FIXED-SIZE, max-number-of-elements=2
  app type tGM_MacBypassNvRamBlockSize: category=VALUE  # NVM data size for Message Authentication Code (MAC) Bypass
  app type tGM_SaBypassNvRamBlockSize: category=VALUE  # NVM data size for Security Access (SA) Bypass
  application array data type tCurrentRSCOTSN_NvRamBlockSize: category=ARRAY  # Size of the NVM storage block for CurrentRepairShopCodeOrTesterSerialNumber
    element Element: category=VALUE, type=UInt8, array-size-semantics=FIXED-SIZE, max-number-of-elements=10
  application array data type tSecondLastRSCOTSN_NvRamBlockSize: category=ARRAY  # Size of the NVM storage block for SecondLastRepairShopCodeOrTesterSerialNumber
    element Element: category=VALUE, type=UInt8, array-size-semantics=FIXED-SIZE, max-number-of-elements=10
  application array data type tLastRSCOTSN_NvRamBlockSize: category=ARRAY  # Size of the NVM storage block for LastRepairShopCodeOrTesterSerialNumber
    element Element: category=VALUE, type=UInt8, array-size-semantics=FIXED-SIZE, max-number-of-elements=10
  4 x app type, all with category=VALUE:
    tStrgMotorOvldProtInc_NvRamBlockSize  # Size of the NVM storage block for SteeringMotorOverloadProtectionIncidents
    tOvldProtPast50IgnCycles_NvRamBlockSize  # Size of the NVM storage block for OverloadProtectionPast50IgnitionCycles
    tCommControlStatusSID28: base-type=sint32, compu {0=COMM_CONTROL_ENABLED_SID_0x28, 1=COMM_CONTROL_DISABLED_SID_0x28}  # Used by UDS service 0x28 to enable or disable communications.
    tCgdNvmJobStatus: base-type=sint32, compu {0=NVM_JOB_INCOMPLETE, 1=NVM_JOB_COMPLETE, 2=NVM_JOB_FAILED}  # Indicates NVM current job status.
package /Predefined_DEV/ImplementationDataTypes
  impl type NvM_RequestResultType: compu {0=NVM_REQ_OK, 1=NVM_REQ_NOT_OK, 2=NVM_REQ_PENDING, 3=NVM_REQ_INTEGRITY_FAILED, 4=NVM_REQ_BLOCK_SKIPPED, 5=NVM_REQ_NV_INVALIDATED, 6=NVM_REQ_CANCELED, 7=NVM_REQ_REDUNDANCY_FAILED, 8=NVM_REQ_RESTORED_FROM_ROM}, implementation-data-type=uint8
package /Predefined_DEV/PortInterfaces
  client server interface NvMService_AC2_SRBS: is-service=true
    4 x operation, all with possible-error=NvMService_AC2_SRBS/E_NOT_OK:
      GetErrorStatus
        arg ErrorStatus: type=NvM_RequestResultType, direction=OUT, server-argument-impl-policy=USE-ARGUMENT-TYPE
      ReadBlock
        arg DstPtr: type=dtRef_VOID, direction=IN, server-argument-impl-policy=USE-ARGUMENT-TYPE
      SetRamBlockStatus
        arg RamBlockStatus: type=boolean, direction=IN, server-argument-impl-policy=USE-ARGUMENT-TYPE
      WriteBlock
        arg SrcPtr: type=dtRef_const_VOID, direction=IN, server-argument-impl-policy=USE-ARGUMENT-TYPE
    error E_NOT_OK: error-code=1
package /MICROSAR/Dem_swc/DataTypes
  18 x impl type:
    Dem_EventIdType: range raw 1..65535, implementation-data-type=uint16
    Dem_RatioIdType: range raw 1..65535, implementation-data-type=uint16
    Dem_DTCStatusMaskType: range raw 0..255, implementation-data-type=uint8
    Dem_OperationCycleIdType: range raw 0..255, implementation-data-type=uint8
    Dem_DTCGroupType: range raw 0..16777215, implementation-data-type=uint32
    Dem_MaxDataValueType: category=ARRAY, sw-calibration-access=READ-ONLY
      element Dem_MaxDataValueTypeElement: array-size=1, array-size-semantics=FIXED-SIZE, implementation-data-type=uint8
    Dem_EventStatusType: compu {0=DEM_EVENT_STATUS_PASSED, 1=DEM_EVENT_STATUS_FAILED, 2=DEM_EVENT_STATUS_PREPASSED, 3=DEM_EVENT_STATUS_PREFAILED}, implementation-data-type=uint8
    Dem_EventStatusExtendedType: compu {1=DEM_UDS_STATUS_TF, 2=DEM_UDS_STATUS_TFTOC, 4=DEM_UDS_STATUS_PDTC, 8=DEM_UDS_STATUS_CDTC, 16=DEM_UDS_STATUS_TNCSLC, 32=DEM_UDS_STATUS_TFSLC, 64=DEM_UDS_STATUS_TNCTOC, 128=DEM_UDS_STATUS_WIR}, implementation-data-type=uint8
    Dem_InitMonitorReasonType: compu {1=DEM_INIT_MONITOR_CLEAR, 2=DEM_INIT_MONITOR_RESTART, 3=DEM_INIT_MONITOR_REENABLED, 4=DEM_INIT_MONITOR_STORAGE_REENABLED}, implementation-data-type=uint8
    Dem_DTCOriginType: compu {1=DEM_DTC_ORIGIN_PRIMARY_MEMORY, 2=DEM_DTC_ORIGIN_MIRROR_MEMORY, 3=DEM_DTC_ORIGIN_PERMANENT_MEMORY, 4=DEM_DTC_ORIGIN_SECONDARY_MEMORY, 4=DEM_DTC_ORIGIN_USERDEFINED_MEMORY_10, 4=DEM_DTC_ORIGIN_USERDEFINED_MEMORY_11, 4=DEM_DTC_ORIGIN_USERDEFINED_MEMORY_12, 4=DEM_DTC_ORIGIN_USERDEFINED_MEMORY_13, 4=DEM_DTC_ORIGIN_USERDEFINED_MEMORY_14, 4=DEM_DTC_ORIGIN_USERDEFINED_MEMORY_15, 4=DEM_DTC_ORIGIN_USERDEFINED_MEMORY_16, 4=DEM_DTC_ORIGIN_USERDEFINED_MEMORY_17, 4=DEM_DTC_ORIGIN_USERDEFINED_MEMORY_18, 4=DEM_DTC_ORIGIN_USERDEFINED_MEMORY_19, 4=DEM_DTC_ORIGIN_USERDEFINED_MEMORY_1A, 4=DEM_DTC_ORIGIN_USERDEFINED_MEMORY_1B, 4=DEM_DTC_ORIGIN_USERDEFINED_MEMORY_1C, 4=DEM_DTC_ORIGIN_USERDEFINED_MEMORY_1D, 4=DEM_DTC_ORIGIN_USERDEFINED_MEMORY_1E, 4=DEM_DTC_ORIGIN_USERDEFINED_MEMORY_1F, 4=DEM_DTC_ORIGIN_USERDEFINED_MEMORY_20, 4=DEM_DTC_ORIGIN_USERDEFINED_MEMORY_21, 4=DEM_DTC_ORIGIN_USERDEFINED_MEMORY_22, 4=DEM_DTC_ORIGIN_USERDEFINED_MEMORY_23, 4=DEM_DTC_ORIGIN_USERDEFINED_MEMORY_24, 4=DEM_DTC_ORIGIN_USERDEFINED_MEMORY_25, 4=DEM_DTC_ORIGIN_USERDEFINED_MEMORY_26, 4=DEM_DTC_ORIGIN_USERDEFINED_MEMORY_27, 4=DEM_DTC_ORIGIN_USERDEFINED_MEMORY_28, 4=DEM_DTC_ORIGIN_USERDEFINED_MEMORY_29, 4=DEM_DTC_ORIGIN_USERDEFINED_MEMORY_2A, 4=DEM_DTC_ORIGIN_USERDEFINED_MEMORY_2B, 4=DEM_DTC_ORIGIN_USERDEFINED_MEMORY_2C, 4=DEM_DTC_ORIGIN_USERDEFINED_MEMORY_2D, 4=DEM_DTC_ORIGIN_USERDEFINED_MEMORY_2E, 4=DEM_DTC_ORIGIN_USERDEFINED_MEMORY_2F, 4=DEM_DTC_ORIGIN_USERDEFINED_MEMORY_30, 4=DEM_DTC_ORIGIN_USERDEFINED_MEMORY_31, 4=DEM_DTC_ORIGIN_USERDEFINED_MEMORY_32, 4=DEM_DTC_ORIGIN_USERDEFINED_MEMORY_33, 4=DEM_DTC_ORIGIN_USERDEFINED_MEMORY_34, 4=DEM_DTC_ORIGIN_USERDEFINED_MEMORY_35, 4=DEM_DTC_ORIGIN_USERDEFINED_MEMORY_36, 4=DEM_DTC_ORIGIN_USERDEFINED_MEMORY_37, 4=DEM_DTC_ORIGIN_USERDEFINED_MEMORY_38, 4=DEM_DTC_ORIGIN_USERDEFINED_MEMORY_39, 4=DEM_DTC_ORIGIN_USERDEFINED_MEMORY_3A, 4=DEM_DTC_ORIGIN_USERDEFINED_MEMORY_3B, 4=DEM_DTC_ORIGIN_USERDEFINED_MEMORY_3C, 4=DEM_DTC_ORIGIN_USERDEFINED_MEMORY_3D, 4=DEM_DTC_ORIGIN_USERDEFINED_MEMORY_3E, 4=DEM_DTC_ORIGIN_USERDEFINED_MEMORY_3F, 4=DEM_DTC_ORIGIN_USERDEFINED_MEMORY_40, 4=DEM_DTC_ORIGIN_USERDEFINED_MEMORY_41, 4=DEM_DTC_ORIGIN_USERDEFINED_MEMORY_42, 4=DEM_DTC_ORIGIN_USERDEFINED_MEMORY_43, 4=DEM_DTC_ORIGIN_USERDEFINED_MEMORY_44, 4=DEM_DTC_ORIGIN_USERDEFINED_MEMORY_45, 4=DEM_DTC_ORIGIN_USERDEFINED_MEMORY_46, 4=DEM_DTC_ORIGIN_USERDEFINED_MEMORY_47, 4=DEM_DTC_ORIGIN_USERDEFINED_MEMORY_48, 4=DEM_DTC_ORIGIN_USERDEFINED_MEMORY_49, 4=DEM_DTC_ORIGIN_USERDEFINED_MEMORY_4A, 4=DEM_DTC_ORIGIN_USERDEFINED_MEMORY_4B, 4=DEM_DTC_ORIGIN_USERDEFINED_MEMORY_4C, 4=DEM_DTC_ORIGIN_USERDEFINED_MEMORY_4D, 4=DEM_DTC_ORIGIN_USERDEFINED_MEMORY_4E, 4=DEM_DTC_ORIGIN_USERDEFINED_MEMORY_4F, 4=DEM_DTC_ORIGIN_USERDEFINED_MEMORY_50, 4=DEM_DTC_ORIGIN_USERDEFINED_MEMORY_51, 4=DEM_DTC_ORIGIN_USERDEFINED_MEMORY_52, 4=DEM_DTC_ORIGIN_USERDEFINED_MEMORY_53, 4=DEM_DTC_ORIGIN_USERDEFINED_MEMORY_54, 4=DEM_DTC_ORIGIN_USERDEFINED_MEMORY_55, 4=DEM_DTC_ORIGIN_USERDEFINED_MEMORY_56, 4=DEM_DTC_ORIGIN_USERDEFINED_MEMORY_57, 4=DEM_DTC_ORIGIN_USERDEFINED_MEMORY_58, 4=DEM_DTC_ORIGIN_USERDEFINED_MEMORY_59, 4=DEM_DTC_ORIGIN_USERDEFINED_MEMORY_5A, 4=DEM_DTC_ORIGIN_USERDEFINED_MEMORY_5B, 4=DEM_DTC_ORIGIN_USERDEFINED_MEMORY_5C, 4=DEM_DTC_ORIGIN_USERDEFINED_MEMORY_5D, 4=DEM_DTC_ORIGIN_USERDEFINED_MEMORY_5E, 4=DEM_DTC_ORIGIN_USERDEFINED_MEMORY_5F, 4=DEM_DTC_ORIGIN_USERDEFINED_MEMORY_60, 4=DEM_DTC_ORIGIN_USERDEFINED_MEMORY_61, 4=DEM_DTC_ORIGIN_USERDEFINED_MEMORY_62, 4=DEM_DTC_ORIGIN_USERDEFINED_MEMORY_63, 4=DEM_DTC_ORIGIN_USERDEFINED_MEMORY_64, 4=DEM_DTC_ORIGIN_USERDEFINED_MEMORY_65, 4=DEM_DTC_ORIGIN_USERDEFINED_MEMORY_66, 4=DEM_DTC_ORIGIN_USERDEFINED_MEMORY_67, 4=DEM_DTC_ORIGIN_USERDEFINED_MEMORY_68, 4=DEM_DTC_ORIGIN_USERDEFINED_MEMORY_69, 4=DEM_DTC_ORIGIN_USERDEFINED_MEMORY_6A, 4=DEM_DTC_ORIGIN_USERDEFINED_MEMORY_6B, 4=DEM_DTC_ORIGIN_USERDEFINED_MEMORY_6C, 4=DEM_DTC_ORIGIN_USERDEFINED_MEMORY_6D, 4=DEM_DTC_ORIGIN_USERDEFINED_MEMORY_6E, 4=DEM_DTC_ORIGIN_USERDEFINED_MEMORY_6F, 4=DEM_DTC_ORIGIN_USERDEFINED_MEMORY_70, 4=DEM_DTC_ORIGIN_USERDEFINED_MEMORY_71, 4=DEM_DTC_ORIGIN_USERDEFINED_MEMORY_72, 4=DEM_DTC_ORIGIN_USERDEFINED_MEMORY_73, 4=DEM_DTC_ORIGIN_USERDEFINED_MEMORY_74, 4=DEM_DTC_ORIGIN_USERDEFINED_MEMORY_75, 4=DEM_DTC_ORIGIN_USERDEFINED_MEMORY_76, 4=DEM_DTC_ORIGIN_USERDEFINED_MEMORY_77, 4=DEM_DTC_ORIGIN_USERDEFINED_MEMORY_78, 4=DEM_DTC_ORIGIN_USERDEFINED_MEMORY_79, 4=DEM_DTC_ORIGIN_USERDEFINED_MEMORY_7A, 4=DEM_DTC_ORIGIN_USERDEFINED_MEMORY_7B, 4=DEM_DTC_ORIGIN_USERDEFINED_MEMORY_7C, 4=DEM_DTC_ORIGIN_USERDEFINED_MEMORY_7D, 4=DEM_DTC_ORIGIN_USERDEFINED_MEMORY_7E, 4=DEM_DTC_ORIGIN_USERDEFINED_MEMORY_7F, 4=DEM_DTC_ORIGIN_USERDEFINED_MEMORY_80, 4=DEM_DTC_ORIGIN_USERDEFINED_MEMORY_81, 4=DEM_DTC_ORIGIN_USERDEFINED_MEMORY_82, 4=DEM_DTC_ORIGIN_USERDEFINED_MEMORY_83, 4=DEM_DTC_ORIGIN_USERDEFINED_MEMORY_84, 4=DEM_DTC_ORIGIN_USERDEFINED_MEMORY_85, 4=DEM_DTC_ORIGIN_USERDEFINED_MEMORY_86, 4=DEM_DTC_ORIGIN_USERDEFINED_MEMORY_87, 4=DEM_DTC_ORIGIN_USERDEFINED_MEMORY_88, 4=DEM_DTC_ORIGIN_USERDEFINED_MEMORY_89, 4=DEM_DTC_ORIGIN_USERDEFINED_MEMORY_8A, 4=DEM_DTC_ORIGIN_USERDEFINED_MEMORY_8B, 4=DEM_DTC_ORIGIN_USERDEFINED_MEMORY_8C, 4=DEM_DTC_ORIGIN_USERDEFINED_MEMORY_8D, 4=DEM_DTC_ORIGIN_USERDEFINED_MEMORY_8E, 4=DEM_DTC_ORIGIN_USERDEFINED_MEMORY_8F, 4=DEM_DTC_ORIGIN_USERDEFINED_MEMORY_90, 4=DEM_DTC_ORIGIN_USERDEFINED_MEMORY_91, 4=DEM_DTC_ORIGIN_USERDEFINED_MEMORY_92, 4=DEM_DTC_ORIGIN_USERDEFINED_MEMORY_93, 4=DEM_DTC_ORIGIN_USERDEFINED_MEMORY_94, 4=DEM_DTC_ORIGIN_USERDEFINED_MEMORY_95, 4=DEM_DTC_ORIGIN_USERDEFINED_MEMORY_96, 4=DEM_DTC_ORIGIN_USERDEFINED_MEMORY_97, 4=DEM_DTC_ORIGIN_USERDEFINED_MEMORY_98, 4=DEM_DTC_ORIGIN_USERDEFINED_MEMORY_99, 4=DEM_DTC_ORIGIN_USERDEFINED_MEMORY_9A, 4=DEM_DTC_ORIGIN_USERDEFINED_MEMORY_9B, 4=DEM_DTC_ORIGIN_USERDEFINED_MEMORY_9C, 4=DEM_DTC_ORIGIN_USERDEFINED_MEMORY_9D, 4=DEM_DTC_ORIGIN_USERDEFINED_MEMORY_9E, 4=DEM_DTC_ORIGIN_USERDEFINED_MEMORY_9F, 4=DEM_DTC_ORIGIN_USERDEFINED_MEMORY_A0, 4=DEM_DTC_ORIGIN_USERDEFINED_MEMORY_A1, 4=DEM_DTC_ORIGIN_USERDEFINED_MEMORY_A2, 4=DEM_DTC_ORIGIN_USERDEFINED_MEMORY_A3, 4=DEM_DTC_ORIGIN_USERDEFINED_MEMORY_A4, 4=DEM_DTC_ORIGIN_USERDEFINED_MEMORY_A5, 4=DEM_DTC_ORIGIN_USERDEFINED_MEMORY_A6, 4=DEM_DTC_ORIGIN_USERDEFINED_MEMORY_A7, 4=DEM_DTC_ORIGIN_USERDEFINED_MEMORY_A8, 4=DEM_DTC_ORIGIN_USERDEFINED_MEMORY_A9, 4=DEM_DTC_ORIGIN_USERDEFINED_MEMORY_AA, 4=DEM_DTC_ORIGIN_USERDEFINED_MEMORY_AB, 4=DEM_DTC_ORIGIN_USERDEFINED_MEMORY_AC, 4=DEM_DTC_ORIGIN_USERDEFINED_MEMORY_AD, 4=DEM_DTC_ORIGIN_USERDEFINED_MEMORY_AE, 4=DEM_DTC_ORIGIN_USERDEFINED_MEMORY_AF, 4=DEM_DTC_ORIGIN_USERDEFINED_MEMORY_B0, 4=DEM_DTC_ORIGIN_USERDEFINED_MEMORY_B1, 4=DEM_DTC_ORIGIN_USERDEFINED_MEMORY_B2, 4=DEM_DTC_ORIGIN_USERDEFINED_MEMORY_B3, 4=DEM_DTC_ORIGIN_USERDEFINED_MEMORY_B4, 4=DEM_DTC_ORIGIN_USERDEFINED_MEMORY_B5, 4=DEM_DTC_ORIGIN_USERDEFINED_MEMORY_B6, 4=DEM_DTC_ORIGIN_USERDEFINED_MEMORY_B7, 4=DEM_DTC_ORIGIN_USERDEFINED_MEMORY_B8, 4=DEM_DTC_ORIGIN_USERDEFINED_MEMORY_B9, 4=DEM_DTC_ORIGIN_USERDEFINED_MEMORY_BA, 4=DEM_DTC_ORIGIN_USERDEFINED_MEMORY_BB, 4=DEM_DTC_ORIGIN_USERDEFINED_MEMORY_BC, 4=DEM_DTC_ORIGIN_USERDEFINED_MEMORY_BD, 4=DEM_DTC_ORIGIN_USERDEFINED_MEMORY_BE, 4=DEM_DTC_ORIGIN_USERDEFINED_MEMORY_BF, 4=DEM_DTC_ORIGIN_USERDEFINED_MEMORY_C0, 4=DEM_DTC_ORIGIN_USERDEFINED_MEMORY_C1, 4=DEM_DTC_ORIGIN_USERDEFINED_MEMORY_C2, 4=DEM_DTC_ORIGIN_USERDEFINED_MEMORY_C3, 4=DEM_DTC_ORIGIN_USERDEFINED_MEMORY_C4, 4=DEM_DTC_ORIGIN_USERDEFINED_MEMORY_C5, 4=DEM_DTC_ORIGIN_USERDEFINED_MEMORY_C6, 4=DEM_DTC_ORIGIN_USERDEFINED_MEMORY_C7, 4=DEM_DTC_ORIGIN_USERDEFINED_MEMORY_C8, 4=DEM_DTC_ORIGIN_USERDEFINED_MEMORY_C9, 4=DEM_DTC_ORIGIN_USERDEFINED_MEMORY_CA, 4=DEM_DTC_ORIGIN_USERDEFINED_MEMORY_CB, 4=DEM_DTC_ORIGIN_USERDEFINED_MEMORY_CC, 4=DEM_DTC_ORIGIN_USERDEFINED_MEMORY_CD, 4=DEM_DTC_ORIGIN_USERDEFINED_MEMORY_CE, 4=DEM_DTC_ORIGIN_USERDEFINED_MEMORY_CF, 4=DEM_DTC_ORIGIN_USERDEFINED_MEMORY_D0, 4=DEM_DTC_ORIGIN_USERDEFINED_MEMORY_D1, 4=DEM_DTC_ORIGIN_USERDEFINED_MEMORY_D2, 4=DEM_DTC_ORIGIN_USERDEFINED_MEMORY_D3, 4=DEM_DTC_ORIGIN_USERDEFINED_MEMORY_D4, 4=DEM_DTC_ORIGIN_USERDEFINED_MEMORY_D5, 4=DEM_DTC_ORIGIN_USERDEFINED_MEMORY_D6, 4=DEM_DTC_ORIGIN_USERDEFINED_MEMORY_D7, 4=DEM_DTC_ORIGIN_USERDEFINED_MEMORY_D8, 4=DEM_DTC_ORIGIN_USERDEFINED_MEMORY_D9, 4=DEM_DTC_ORIGIN_USERDEFINED_MEMORY_DA, 4=DEM_DTC_ORIGIN_USERDEFINED_MEMORY_DB, 4=DEM_DTC_ORIGIN_USERDEFINED_MEMORY_DC, 4=DEM_DTC_ORIGIN_USERDEFINED_MEMORY_DD, 4=DEM_DTC_ORIGIN_USERDEFINED_MEMORY_DE, 4=DEM_DTC_ORIGIN_USERDEFINED_MEMORY_DF, 4=DEM_DTC_ORIGIN_USERDEFINED_MEMORY_E0, 4=DEM_DTC_ORIGIN_USERDEFINED_MEMORY_E1, 4=DEM_DTC_ORIGIN_USERDEFINED_MEMORY_E2, 4=DEM_DTC_ORIGIN_USERDEFINED_MEMORY_E3, 4=DEM_DTC_ORIGIN_USERDEFINED_MEMORY_E4, 4=DEM_DTC_ORIGIN_USERDEFINED_MEMORY_E5, 4=DEM_DTC_ORIGIN_USERDEFINED_MEMORY_E6, 4=DEM_DTC_ORIGIN_USERDEFINED_MEMORY_E7, 4=DEM_DTC_ORIGIN_USERDEFINED_MEMORY_E8, 4=DEM_DTC_ORIGIN_USERDEFINED_MEMORY_E9, 4=DEM_DTC_ORIGIN_USERDEFINED_MEMORY_EA, 4=DEM_DTC_ORIGIN_USERDEFINED_MEMORY_EB, 4=DEM_DTC_ORIGIN_USERDEFINED_MEMORY_EC, 4=DEM_DTC_ORIGIN_USERDEFINED_MEMORY_ED, 4=DEM_DTC_ORIGIN_USERDEFINED_MEMORY_EE, 4=DEM_DTC_ORIGIN_USERDEFINED_MEMORY_EF, 4=DEM_DTC_ORIGIN_USERDEFINED_MEMORY_F0, 4=DEM_DTC_ORIGIN_USERDEFINED_MEMORY_F1, 4=DEM_DTC_ORIGIN_USERDEFINED_MEMORY_F2, 4=DEM_DTC_ORIGIN_USERDEFINED_MEMORY_F3, 4=DEM_DTC_ORIGIN_USERDEFINED_MEMORY_F4, 4=DEM_DTC_ORIGIN_USERDEFINED_MEMORY_F5, 4=DEM_DTC_ORIGIN_USERDEFINED_MEMORY_F6, 4=DEM_DTC_ORIGIN_USERDEFINED_MEMORY_F7, 4=DEM_DTC_ORIGIN_USERDEFINED_MEMORY_F8, 4=DEM_DTC_ORIGIN_USERDEFINED_MEMORY_F9, 4=DEM_DTC_ORIGIN_USERDEFINED_MEMORY_FA, 4=DEM_DTC_ORIGIN_USERDEFINED_MEMORY_FB, 4=DEM_DTC_ORIGIN_USERDEFINED_MEMORY_FC, 4=DEM_DTC_ORIGIN_USERDEFINED_MEMORY_FD, 4=DEM_DTC_ORIGIN_USERDEFINED_MEMORY_FE, 4=DEM_DTC_ORIGIN_USERDEFINED_MEMORY_FF}, implementation-data-type=uint8
    Dem_DTCFormatType: compu {0=DEM_DTC_FORMAT_OBD, 1=DEM_DTC_FORMAT_UDS, 2=DEM_DTC_FORMAT_J1939}, implementation-data-type=uint8
    Dem_OperationCycleStateType: compu {0=DEM_CYCLE_STATE_START, 1=DEM_CYCLE_STATE_END}, implementation-data-type=uint8
    Dem_IndicatorStatusType: compu {0=DEM_INDICATOR_OFF, 1=DEM_INDICATOR_CONTINUOUS, 2=DEM_INDICATOR_BLINKING, 3=DEM_INDICATOR_BLINK_CONT, 4=DEM_INDICATOR_SLOW_FLASH, 5=DEM_INDICATOR_FAST_FLASH, 6=DEM_INDICATOR_ON_DEMAND, 7=DEM_INDICATOR_SHORT}, implementation-data-type=uint8
    Dem_DTCKindType: compu {1=DEM_DTC_KIND_ALL_DTCS, 2=DEM_DTC_KIND_EMISSION_REL_DTCS}, implementation-data-type=uint8
    Dem_IumprDenomCondIdType: compu {1=DEM_IUMPR_GENERAL_DENOMINATOR, 2=DEM_IUMPR_DEN_COND_COLDSTART, 3=DEM_IUMPR_DEN_COND_EVAP, 4=DEM_IUMPR_DEN_COND_500MI}, implementation-data-type=uint8
    Dem_IumprDenomCondStatusType: compu {0=DEM_IUMPR_DEN_STATUS_NOT_REACHED, 1=DEM_IUMPR_DEN_STATUS_REACHED, 2=DEM_IUMPR_DEN_STATUS_INHIBITED}, implementation-data-type=uint8
    Dem_DebounceResetStatusType: compu {0=DEM_DEBOUNCE_STATUS_FREEZE, 1=DEM_DEBOUNCE_STATUS_RESET}, implementation-data-type=uint8
    Dem_DebouncingStateType: compu {1=DEM_TEMPORARILY_DEFECTIVE, 2=DEM_FINALLY_DEFECTIVE, 4=DEM_TEMPORARILY_HEALED, 8=DEM_TEST_COMPLETE, 16=DEM_DTR_UPDATE}, implementation-data-type=uint8
package /MICROSAR/Dem_swc/Interfaces
  10 x client server interface, all with is-service=true, service-kind=DIAGNOSTIC-EVENT-MANAGER:
    CddIf
      operation ClearDTC: possible-error=[CddIf/DEM_CLEAR_WRONG_DTC, CddIf/DEM_CLEAR_WRONG_DTCORIGIN, CddIf/DEM_CLEAR_FAILED, CddIf/DEM_CLEAR_PENDING, CddIf/DEM_CLEAR_BUSY, CddIf/DEM_CLEAR_MEMORY_ERROR]
        arg DTC: type=uint32, direction=IN
        arg DTCFormat: type=Dem_DTCFormatType, direction=IN
        arg DTCOrigin: type=Dem_DTCOriginType, direction=IN
      6 x error:
        DEM_CLEAR_WRONG_DTC: error-code=1
        DEM_CLEAR_WRONG_DTCORIGIN: error-code=2
        DEM_CLEAR_FAILED: error-code=3
        DEM_CLEAR_PENDING: error-code=4
        DEM_CLEAR_BUSY: error-code=5
        DEM_CLEAR_MEMORY_ERROR: error-code=6
    DemServices
      operation GetPostRunRequested: possible-error=DemServices/E_NOT_OK
        arg IsRequested: type=boolean, direction=OUT
      operation GetDTCStatusAvailabilityMask: possible-error=DemServices/E_NOT_OK
        arg DTCStatusMask: type=uint8, direction=OUT
      error E_NOT_OK: error-code=1
    GeneralDiagnosticInfo
      9 x operation:
        GetEventStatus: possible-error=GeneralDiagnosticInfo/E_NOT_OK
          arg EventId: type=Dem_EventIdType, direction=IN
          arg EventStatusExtended: type=Dem_EventStatusExtendedType, direction=OUT
        GetEventFailed: possible-error=GeneralDiagnosticInfo/E_NOT_OK
          arg EventId: type=Dem_EventIdType, direction=IN
          arg EventFailed: type=boolean, direction=OUT
        GetEventTested: possible-error=GeneralDiagnosticInfo/E_NOT_OK
          arg EventId: type=Dem_EventIdType, direction=IN
          arg EventTested: type=boolean, direction=OUT
        GetDTCOfEvent: possible-error=[GeneralDiagnosticInfo/E_NOT_OK, GeneralDiagnosticInfo/DEM_E_NO_DTC_AVAILABLE]
          arg EventId: type=Dem_EventIdType, direction=IN
          arg DTCFormat: type=Dem_DTCFormatType, direction=IN
          arg DTCOfEvent: type=uint32, direction=OUT
        GetFaultDetectionCounter: possible-error=[GeneralDiagnosticInfo/E_NOT_OK, GeneralDiagnosticInfo/DEM_E_NO_FDC_AVAILABLE]
          arg EventId: type=Dem_EventIdType, direction=IN
          arg FaultDetectionCounter: type=sint8, direction=OUT
        GetEventFreezeFrameData: possible-error=[GeneralDiagnosticInfo/E_NOT_OK, GeneralDiagnosticInfo/DEM_E_NODATAAVAILABLE, GeneralDiagnosticInfo/DEM_E_WRONG_RECORDNUMBER, GeneralDiagnosticInfo/DEM_E_WRONG_DIDNUMBER]
          5 x arg:
            EventId: type=Dem_EventIdType, direction=IN
            RecordNumber: type=uint8, direction=IN
            ReportTotalRecord: type=boolean, direction=IN
            DataId: type=uint16, direction=IN
            DestBuffer: type=Dem_MaxDataValueType, direction=OUT
        GetEventExtendedDataRecord: possible-error=[GeneralDiagnosticInfo/E_NOT_OK, GeneralDiagnosticInfo/DEM_E_NODATAAVAILABLE, GeneralDiagnosticInfo/DEM_E_WRONG_RECORDNUMBER]
          arg EventId: type=Dem_EventIdType, direction=IN
          arg RecordNumber: type=uint8, direction=IN
          arg DestBuffer: type=Dem_MaxDataValueType, direction=OUT
        GetEventEnableCondition: possible-error=GeneralDiagnosticInfo/E_NOT_OK
          arg EventId: type=Dem_EventIdType, direction=IN
          arg ConditionFullfilled: type=boolean, direction=OUT
        GetDebouncingOfEvent: possible-error=GeneralDiagnosticInfo/E_NOT_OK
          arg EventId: type=Dem_EventIdType, direction=IN
          arg DebouncingState: type=Dem_DebouncingStateType, direction=OUT
      6 x error:
        E_NOT_OK: error-code=1
        DEM_E_NO_DTC_AVAILABLE: error-code=2
        DEM_E_NO_FDC_AVAILABLE: error-code=3
        DEM_E_NODATAAVAILABLE: error-code=48
        DEM_E_WRONG_RECORDNUMBER: error-code=49
        DEM_E_WRONG_DIDNUMBER: error-code=50
    DiagnosticInfo
      9 x operation:
        GetEventStatus: possible-error=DiagnosticInfo/E_NOT_OK
          arg EventStatusExtended: type=Dem_EventStatusExtendedType, direction=OUT
        GetEventFailed: possible-error=DiagnosticInfo/E_NOT_OK
          arg EventFailed: type=boolean, direction=OUT
        GetEventTested: possible-error=DiagnosticInfo/E_NOT_OK
          arg EventTested: type=boolean, direction=OUT
        GetDTCOfEvent: possible-error=[DiagnosticInfo/E_NOT_OK, DiagnosticInfo/DEM_E_NO_DTC_AVAILABLE]
          arg DTCFormat: type=Dem_DTCFormatType, direction=IN
          arg DTCOfEvent: type=uint32, direction=OUT
        GetFaultDetectionCounter: possible-error=[DiagnosticInfo/E_NOT_OK, DiagnosticInfo/DEM_E_NO_FDC_AVAILABLE]
          arg FaultDetectionCounter: type=sint8, direction=OUT
        GetEventFreezeFrameData: possible-error=[DiagnosticInfo/E_NOT_OK, DiagnosticInfo/DEM_E_NODATAAVAILABLE, DiagnosticInfo/DEM_E_WRONG_RECORDNUMBER, DiagnosticInfo/DEM_E_WRONG_DIDNUMBER]
          4 x arg:
            RecordNumber: type=uint8, direction=IN
            ReportTotalRecord: type=boolean, direction=IN
            DataId: type=uint16, direction=IN
            DestBuffer: type=Dem_MaxDataValueType, direction=OUT
        GetEventExtendedDataRecord: possible-error=[DiagnosticInfo/E_NOT_OK, DiagnosticInfo/DEM_E_NODATAAVAILABLE, DiagnosticInfo/DEM_E_WRONG_RECORDNUMBER]
          arg RecordNumber: type=uint8, direction=IN
          arg DestBuffer: type=Dem_MaxDataValueType, direction=OUT
        GetEventEnableCondition: possible-error=DiagnosticInfo/E_NOT_OK
          arg ConditionFullfilled: type=boolean, direction=OUT
        GetDebouncingOfEvent: possible-error=DiagnosticInfo/E_NOT_OK
          arg DebouncingState: type=Dem_DebouncingStateType, direction=OUT
      6 x error:
        E_NOT_OK: error-code=1
        DEM_E_NO_DTC_AVAILABLE: error-code=2
        DEM_E_NO_FDC_AVAILABLE: error-code=3
        DEM_E_NODATAAVAILABLE: error-code=48
        DEM_E_WRONG_RECORDNUMBER: error-code=49
        DEM_E_WRONG_DIDNUMBER: error-code=50
    DiagnosticMonitor
      10 x operation:
        SetEventStatus: possible-error=DiagnosticMonitor/E_NOT_OK
          arg EventStatus: type=Dem_EventStatusType, direction=IN
        ResetEventStatus: possible-error=DiagnosticMonitor/E_NOT_OK
        ResetEventDebounceStatus: possible-error=DiagnosticMonitor/E_NOT_OK
          arg DebounceResetStatus: type=Dem_DebounceResetStatusType, direction=IN
        GetEventStatus: possible-error=DiagnosticMonitor/E_NOT_OK
          arg EventStatusExtended: type=Dem_EventStatusExtendedType, direction=OUT
        GetEventFailed: possible-error=DiagnosticMonitor/E_NOT_OK
          arg EventFailed: type=boolean, direction=OUT
        GetEventTested: possible-error=DiagnosticMonitor/E_NOT_OK
          arg EventTested: type=boolean, direction=OUT
        GetDTCOfEvent: possible-error=[DiagnosticMonitor/E_NOT_OK, DiagnosticMonitor/DEM_E_NO_DTC_AVAILABLE]
          arg DTCFormat: type=Dem_DTCFormatType, direction=IN
          arg DTCOfEvent: type=uint32, direction=OUT
        GetFaultDetectionCounter: possible-error=[DiagnosticMonitor/E_NOT_OK, DiagnosticMonitor/DEM_E_NO_FDC_AVAILABLE]
          arg FaultDetectionCounter: type=sint8, direction=OUT
        GetEventFreezeFrameData: possible-error=[DiagnosticMonitor/E_NOT_OK, DiagnosticMonitor/DEM_E_NODATAAVAILABLE, DiagnosticMonitor/DEM_E_WRONG_RECORDNUMBER, DiagnosticMonitor/DEM_E_WRONG_DIDNUMBER]
          4 x arg:
            RecordNumber: type=uint8, direction=IN
            ReportTotalRecord: type=boolean, direction=IN
            DataId: type=uint16, direction=IN
            DestBuffer: type=Dem_MaxDataValueType, direction=OUT
        GetEventExtendedDataRecord: possible-error=[DiagnosticMonitor/E_NOT_OK, DiagnosticMonitor/DEM_E_NODATAAVAILABLE, DiagnosticMonitor/DEM_E_WRONG_RECORDNUMBER]
          arg RecordNumber: type=uint8, direction=IN
          arg DestBuffer: type=Dem_MaxDataValueType, direction=OUT
      6 x error:
        E_NOT_OK: error-code=1
        DEM_E_NO_DTC_AVAILABLE: error-code=2
        DEM_E_NO_FDC_AVAILABLE: error-code=3
        DEM_E_NODATAAVAILABLE: error-code=48
        DEM_E_WRONG_RECORDNUMBER: error-code=49
        DEM_E_WRONG_DIDNUMBER: error-code=50
    DcmIf
      5 x operation:
        DcmClearDTC: possible-error=[DcmIf/DEM_CLEAR_WRONG_DTC, DcmIf/DEM_CLEAR_WRONG_DTCORIGIN, DcmIf/DEM_CLEAR_FAILED, DcmIf/DEM_CLEAR_PENDING, DcmIf/DEM_CLEAR_BUSY, DcmIf/DEM_CLEAR_MEMORY_ERROR]
          arg DTC: type=uint32, direction=IN
          arg DTCFormat: type=Dem_DTCFormatType, direction=IN
          arg DTCOrigin: type=Dem_DTCOriginType, direction=IN
        DcmGetNextFilteredDTCAndFDC: possible-error=DEM_FILTERED_NO_MATCHING_DTC
          arg DTC: type=uint32, direction=OUT
          arg DTCFaultDetectionCounter: type=sint8, direction=OUT
        DcmEnableDTCSetting: possible-error=[DEM_CONTROL_DTC_SETTING_N_OK, DEM_CONTROL_DTC_WRONG_DTCGROUP]
          arg DTCGroup: type=Dem_DTCGroupType, direction=IN
          arg DTCKind: type=Dem_DTCKindType, direction=IN
        DcmGetFreezeFrameDataByDTC: possible-error=[DEM_GET_FFDATABYDTC_WRONG_DTC, DEM_GET_FFDATABYDTC_WRONG_DTCORIGIN, DEM_GET_FFDATABYDTC_WRONG_RECORDNUMBER, DEM_GET_FFDATABYDTC_WRONG_BUFFERSIZE, DEM_GET_FFDATABYDTC_PENDING]
          5 x arg:
            DTC: type=uint32, direction=IN
            DTCOrigin: type=Dem_DTCOriginType, direction=IN
            RecordNumber: type=uint8, direction=IN
            DestBuffer: type=uint8, direction=OUT
            BufSize: type=uint16, direction=INOUT
        DcmGetExtendedDataRecordByDTC: possible-error=[DEM_RECORD_WRONG_DTC, DEM_RECORD_WRONG_DTCORIGIN, DEM_RECORD_WRONG_NUMBER, DEM_RECORD_WRONG_BUFFERSIZE, DEM_RECORD_PENDING]
          5 x arg:
            DTC: type=uint32, direction=IN
            DTCOrigin: type=Dem_DTCOriginType, direction=IN
            ExtendedDataNumber: type=uint8, direction=IN
            DestBuffer: type=uint8, direction=OUT
            BufSize: type=uint16, direction=INOUT
      19 x error:
        DEM_CLEAR_WRONG_DTC: error-code=1
        DEM_CONTROL_DTC_SETTING_N_OK: error-code=1
        DEM_FILTERED_NO_MATCHING_DTC: error-code=1
        DEM_GET_FFDATABYDTC_WRONG_DTC: error-code=1
        DEM_RECORD_WRONG_DTC: error-code=1
        DEM_CLEAR_WRONG_DTCORIGIN: error-code=2
        DEM_CONTROL_DTC_WRONG_DTCGROUP: error-code=2
        DEM_GET_FFDATABYDTC_WRONG_DTCORIGIN: error-code=2
        DEM_RECORD_WRONG_DTCORIGIN: error-code=2
        DEM_CLEAR_FAILED: error-code=3
        DEM_GET_FFDATABYDTC_WRONG_RECORDNUMBER: error-code=3
        DEM_RECORD_WRONG_NUMBER: error-code=3
        DEM_CLEAR_PENDING: error-code=4
        DEM_GET_FFDATABYDTC_WRONG_BUFFERSIZE: error-code=4
        DEM_RECORD_WRONG_BUFFERSIZE: error-code=4
        DEM_CLEAR_BUSY: error-code=5
        DEM_GET_FFDATABYDTC_PENDING: error-code=5
        DEM_RECORD_PENDING: error-code=5
        DEM_CLEAR_MEMORY_ERROR: error-code=6
    OperationCycle
      operation SetOperationCycleState: possible-error=OperationCycle/E_NOT_OK
        arg CycleState: type=Dem_OperationCycleStateType, direction=IN
      error E_NOT_OK: error-code=1
    GeneralCallbackEventStatusChange
      operation EventStatusChanged
        arg EventId: type=Dem_EventIdType, direction=IN
        arg EventStatusOld: type=Dem_EventStatusExtendedType, direction=IN
        arg EventStatusNew: type=Dem_EventStatusExtendedType, direction=IN
    EvMemOverflowIndication
      operation GetEventMemoryOverflow: possible-error=EvMemOverflowIndication/E_NOT_OK
        arg OverflowIndication: type=boolean, direction=OUT
      operation GetNumberOfEventMemoryEntries: possible-error=EvMemOverflowIndication/E_NOT_OK
        arg NumberOfEventMemoryEntries: type=uint8, direction=OUT
      error E_NOT_OK: error-code=1
    EnableCondition
      operation SetEnableCondition: possible-error=EnableCondition/E_NOT_OK
        arg ConditionFulfilled: type=boolean, direction=IN
      error E_NOT_OK: error-code=1
